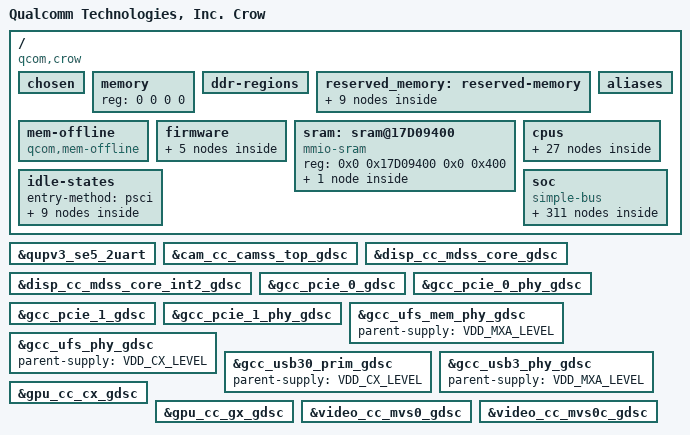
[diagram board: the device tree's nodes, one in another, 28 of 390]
#include <dt-bindings/clock/qcom,rpmh.h>
#include <dt-bindings/clock/qcom,camcc-crow.h>
#include <dt-bindings/clock/qcom,dispcc-crow.h>
#include <dt-bindings/clock/qcom,gcc-crow.h>
#include <dt-bindings/clock/qcom,gpucc-crow.h>
#include <dt-bindings/clock/qcom,tcsrcc-kalama.h>
#include <dt-bindings/clock/qcom,videocc-crow.h>
#include <dt-bindings/interconnect/qcom,icc.h>
#include <dt-bindings/interconnect/qcom,crow.h>
#include <dt-bindings/interrupt-controller/arm-gic.h>
#include <dt-bindings/soc/qcom,ipcc.h>
#include <dt-bindings/soc/qcom,rpmh-rsc.h>
#include <dt-bindings/regulator/qcom,rpmh-regulator-levels.h>
#include <dt-bindings/gpio/gpio.h>
#include <dt-bindings/spmi/spmi.h>
#include <dt-bindings/power/qcom-aoss-qmp.h>
#include <dt-bindings/clock/qcom,aop-qmp.h>

/ {
	model = "Qualcomm Technologies, Inc. Crow";
	compatible = "qcom,crow";
	qcom,msm-id = <608 0x10000>, <644 0x10000>;
	interrupt-parent = <&intc>;

	#address-cells = <2>;
	#size-cells = <2>;

	chosen: chosen {
		bootargs = "console=ttyMSM0,115200n8 loglevel=6 kpti=0 loop.max_part=7 allow_mismatched_32bit_el0 log_buf_len=256K kernel.panic_on_rcu_stall=1 service_locator.enable=1 msm_rtb.filter=0x237 rcupdate.rcu_expedited=1 rcu_nocbs=0-7 ftrace_dump_on_oops printk.console_no_auto_verbose=1 kasan=off can.stats_timer=0 pcie_ports=compat cpufreq.default_governor=performance cgroup.memory=nokmem,nosocket swiotlb=noforce disable_dma32=on page_poison=on";
		stdout-path = "/soc/qcom,qupv3_0_geni_se@8c0000/qcom,qup_uart@894000";
	};

	memory { device_type = "memory"; reg = <0 0 0 0>; };

	ddr-regions { };

	reserved_memory: reserved-memory { };

	mem-offline {
		compatible = "qcom,mem-offline";
		offline-sizes = <0x1 0x40000000 0x0 0x40000000>,
				<0x1 0xc0000000 0x0 0x80000000>,
				<0x2 0xc0000000 0x1 0x00000000>;
		granule = <512>;
		mboxes = <&qmp_aop 0>;
	};

	firmware: firmware {};

	aliases: aliases {
		serial0 = &qupv3_se5_2uart;
		ufshc1 = &ufshc_mem; /* Embedded UFS Slot */
		mmc1 = &sdhc_2; /* SDC2 SD card slot */
		hsuart0 = &qupv3_se10_4uart;
	};

	sram: sram@17D09400 {
		#address-cells = <2>;
		#size-cells = <2>;
		compatible = "mmio-sram";
		reg = <0x0 0x17D09400 0x0 0x400>;
		ranges = <0x0 0x0 0x0 0x17D09400 0x0 0x400>;

		cpu_scp_lpri: scmi-shmem@0 {
			compatible = "arm,scmi-shmem";
			reg = <0x0 0x0 0x0 0x400>;
		};
	};

	cpus {
		#address-cells = <2>;
		#size-cells = <0>;

		CPU0: cpu@0 {
			device_type = "cpu";
			compatible = "qcom,kryo";
			reg = <0x0 0x0>;
			enable-method = "psci";
			cpu-idle-states = <&SILVER_OFF &SILVER_RAIL_OFF>;
			power-domains = <&CPU_PD0>;
			power-domain-names = "psci";
			qcom,freq-domain = <&cpufreq_hw 0>;
			next-level-cache = <&L2_0>;
			capacity-dmips-mhz = <1024>;
			dynamic-power-coefficient = <100>;
			#cooling-cells = <2>;
			L2_0: l2-cache {
				compatible = "arm,arch-cache";
				cache-level = <2>;
				next-level-cache = <&L3_0>;
				L3_0: l3-cache {
					compatible = "arm,arch-cache";
					cache-level = <3>;
				};
			};
		};

		CPU1: cpu@100 {
			device_type = "cpu";
			compatible = "qcom,kryo";
			reg = <0x0 0x100>;
			enable-method = "psci";
			cpu-idle-states = <&SILVER_OFF &SILVER_RAIL_OFF>;
			power-domains = <&CPU_PD1>;
			power-domain-names = "psci";
			qcom,freq-domain = <&cpufreq_hw 0>;
			next-level-cache = <&L2_0>;
			capacity-dmips-mhz = <1024>;
			dynamic-power-coefficient = <100>;
			#cooling-cells = <2>;
		};

		CPU2: cpu@200 {
			device_type = "cpu";
			compatible = "qcom,kryo";
			reg = <0x0 0x200>;
			enable-method = "psci";
			cpu-idle-states = <&SILVER_OFF &SILVER_RAIL_OFF>;
			power-domains = <&CPU_PD2>;
			power-domain-names = "psci";
			qcom,freq-domain = <&cpufreq_hw 0>;
			next-level-cache = <&L2_2>;
			capacity-dmips-mhz = <1024>;
			dynamic-power-coefficient = <100>;
			#cooling-cells = <2>;
			L2_2: l2-cache {
				compatible = "arm,arch-cache";
				cache-level = <2>;
				next-level-cache = <&L3_0>;
			};
		};

		CPU3: cpu@300 {
			device_type = "cpu";
			compatible = "qcom,kryo";
			reg = <0x0 0x300>;
			enable-method = "psci";
			cpu-idle-states = <&SILVER_OFF &SILVER_RAIL_OFF>;
			power-domains = <&CPU_PD3>;
			power-domain-names = "psci";
			qcom,freq-domain = <&cpufreq_hw 0>;
			next-level-cache = <&L2_2>;
			capacity-dmips-mhz = <1024>;
			dynamic-power-coefficient = <100>;
			#cooling-cells = <2>;
		};

		CPU4: cpu@400 {
			device_type = "cpu";
			compatible = "qcom,kryo";
			reg = <0x0 0x400>;
			enable-method = "psci";
			cpu-idle-states = <&GOLD_OFF &GOLD_RAIL_OFF>;
			power-domains = <&CPU_PD4>;
			power-domain-names = "psci";
			qcom,freq-domain = <&cpufreq_hw 1>;
			next-level-cache = <&L2_4>;
			capacity-dmips-mhz = <1843>;
			dynamic-power-coefficient = <226>;
			#cooling-cells = <2>;
			L2_4: l2-cache {
				compatible = "arm,arch-cache";
				cache-level = <2>;
				next-level-cache = <&L3_0>;
			};
		};

		CPU5: cpu@500 {
			device_type = "cpu";
			compatible = "qcom,kryo";
			reg = <0x0 0x500>;
			enable-method = "psci";
			cpu-idle-states = <&GOLD_OFF &GOLD_RAIL_OFF>;
			power-domains = <&CPU_PD5>;
			power-domain-names = "psci";
			qcom,freq-domain = <&cpufreq_hw 1>;
			next-level-cache = <&L2_5>;
			capacity-dmips-mhz = <1843>;
			dynamic-power-coefficient = <226>;
			#cooling-cells = <2>;
			L2_5: l2-cache {
				compatible = "arm,arch-cache";
				cache-level = <2>;
				next-level-cache = <&L3_0>;
			};
		};

		CPU6: cpu@600 {
			device_type = "cpu";
			compatible = "qcom,kryo";
			reg = <0x0 0x600>;
			enable-method = "psci";
			cpu-idle-states = <&GOLD_OFF &GOLD_RAIL_OFF>;
			power-domains = <&CPU_PD6>;
			power-domain-names = "psci";
			qcom,freq-domain = <&cpufreq_hw 1>;
			next-level-cache = <&L2_6>;
			capacity-dmips-mhz = <1843>;
			dynamic-power-coefficient = <226>;
			#cooling-cells = <2>;
			L2_6: l2-cache {
				compatible = "arm,arch-cache";
				cache-level = <2>;
				next-level-cache = <&L3_0>;
				};
		};

		CPU7: cpu@700 {
			device_type = "cpu";
			compatible = "qcom,kryo";
			reg = <0x0 0x700>;
			enable-method = "psci";
			cpu-idle-states = <&GOLD_PLUS_OFF &GOLD_PLUS_RAIL_OFF>;
			power-domains = <&CPU_PD7>;
			power-domain-names = "psci";
			qcom,freq-domain = <&cpufreq_hw 2>;
			next-level-cache = <&L2_7>;
			capacity-dmips-mhz = <1853>;
			dynamic-power-coefficient = <245>;
			#cooling-cells = <2>;
			L2_7: l2-cache {
				compatible = "arm,arch-cache";
				cache-level = <2>;
				next-level-cache = <&L3_0>;
			};
		};

		cpu-map {
			cluster0 {
				core0 {
					cpu = <&CPU0>;
				};

				core1 {
					cpu = <&CPU1>;
				};

				core2 {
					cpu = <&CPU2>;
				};

				core3 {
					cpu = <&CPU3>;
				};
			};

			cluster1 {
				core0 {
					cpu = <&CPU4>;
				};

				core1 {
					cpu = <&CPU5>;
				};

				core2 {
					cpu = <&CPU6>;
				};
			};

			cluster2 {
				core0 {
					cpu = <&CPU7>;
				};
			};
		};
	};

	idle-states {
		entry-method = "psci";

		SILVER_OFF: silver-c3 {  /* C3 */
			compatible = "arm,idle-state";
			idle-state-name = "pc";
			entry-latency-us = <250>;
			exit-latency-us = <900>;
			min-residency-us = <3200>;
			arm,psci-suspend-param = <0x40000003>;
			local-timer-stop;
		};

		SILVER_RAIL_OFF: silver-c4 {  /* C4 */
			compatible = "arm,idle-state";
			idle-state-name = "rail-pc";
			entry-latency-us = <550>;
			exit-latency-us = <750>;
			min-residency-us = <6700>;
			arm,psci-suspend-param = <0x40000004>;
			local-timer-stop;
		};

		GOLD_OFF: gold-c3 {  /* C3 */
			compatible = "arm,idle-state";
			idle-state-name = "pc";
			entry-latency-us = <400>;
			exit-latency-us = <1100>;
			min-residency-us = <4011>;
			arm,psci-suspend-param = <0x40000003>;
			local-timer-stop;
		};

		GOLD_RAIL_OFF: gold-c4 {  /* C4 */
			compatible = "arm,idle-state";
			idle-state-name = "rail-pc";
			entry-latency-us = <600>;
			exit-latency-us = <1300>;
			min-residency-us = <8136>;
			arm,psci-suspend-param = <0x40000004>;
			local-timer-stop;
		};

		GOLD_PLUS_OFF: gold-plus-c3 {  /* C3 */
			compatible = "arm,idle-state";
			idle-state-name = "pc";
			entry-latency-us = <450>;
			exit-latency-us = <1200>;
			min-residency-us = <6230>;
			arm,psci-suspend-param = <0x40000003>;
			local-timer-stop;
		};

		GOLD_PLUS_RAIL_OFF: gold-plus-c4 {  /* C4 */
			compatible = "arm,idle-state";
			idle-state-name = "rail-pc";
			entry-latency-us = <500>;
			exit-latency-us = <1350>;
			min-residency-us = <7480>;
			arm,psci-suspend-param = <0x40000004>;
			local-timer-stop;
		};

		CLUSTER_PWR_DN: cluster-d4 { /* D4 */
			compatible = "domain-idle-state";
			idle-state-name = "l3-off";
			entry-latency-us = <750>;
			exit-latency-us = <2350>;
			min-residency-us = <9144>;
			arm,psci-suspend-param = <0x41000044>;
		};

		CX_RET: cx-ret { /* Cx Ret */
			compatible = "domain-idle-state";
			idle-state-name = "cx-ret";
			entry-latency-us = <1561>;
			exit-latency-us = <2801>;
			min-residency-us = <8550>;
			arm,psci-suspend-param = <0x41001344>;
		};

		APSS_OFF: cluster-e3 { /* E3 */
			compatible = "domain-idle-state";
			idle-state-name = "llcc-off";
			entry-latency-us = <2800>;
			exit-latency-us = <4400>;
			min-residency-us = <10150>;
			arm,psci-suspend-param = <0x4100b344>;
		};
	};

	soc: soc { };
};

#include "crow-reserved-memory.dtsi"
#include "crow-dma-heaps.dtsi"
#include "msm-arm-smmu-crow.dtsi"
#include "crow-coresight.dtsi"
#include "crow-debug.dtsi"

&reserved_memory {
	#address-cells = <2>;
	#size-cells = <2>;
	ranges;

	/* global autoconfigured region for contiguous allocations */
	system_cma: linux,cma {
		compatible = "shared-dma-pool";
		alloc-ranges = <0x0 0x00000000 0x0 0xffffffff>;
		reusable;
		alignment = <0x0 0x400000>;
		size = <0x0 0x2000000>;
		linux,cma-default;
	};

	ramoops_mem: ramoops_region {
		compatible = "ramoops";
		alloc-ranges = <0x0 0x00000000 0xffffffff 0xffffffff>;
		size = <0x0 0x200000>;
		pmsg-size = <0x200000>;
		mem-type = <2>;
	};

	kinfo_mem: debug_kinfo_region {
		alloc-ranges = <0x0 0x00000000 0xffffffff 0xffffffff>;
		size = <0x0 0x1000>;
		no-map;
	};

	qseecom_mem: qseecom_region {
		compatible = "shared-dma-pool";
		alloc-ranges = <0x0 0x00000000 0x0 0xffffffff>;
		reusable;
		alignment = <0x0 0x400000>;
		size = <0x0 0xC00000>;
	};

	qseecom_ta_mem: qseecom_ta_region {
		compatible = "shared-dma-pool";
		alloc-ranges = <0x0 0x00000000 0x0 0xffffffff>;
		reusable;
		alignment = <0x0 0x400000>;
		size = <0x0 0xC00000>;
	};

	adsp_mem_heap: adsp_heap_region {
		compatible = "shared-dma-pool";
		alloc-ranges = <0x0 0x00000000 0x0 0xffffffff>;
		reusable;
		alignment = <0x0 0x400000>;
		size = <0x0 0xC00000>;
	};

	cdsp_secure_heap: secure_cdsp_region { /* Secure DSP */
		compatible = "shared-dma-pool";
		alloc-ranges = <0x0 0x00000000 0x0 0xffffffff>;
		reusable;
		alignment = <0x0 0x400000>;
		size = <0x0 0x2800000>;
	};

	va_md_mem: va_md_mem_region {
		compatible = "shared-dma-pool";
		alloc-ranges = <0x0 0x00000000 0x0 0xffffffff>;
		reusable;
		size = <0 0x1000000>;
	};

	non_secure_display_memory: non_secure_display_region {
		compatible = "shared-dma-pool";
		reusable;
		alloc-ranges = <0x0 0x00000000 0x0 0xffffffff>;
		size = <0x0 0xa400000>;
		alignment = <0x0 0x400000>;
	};
};

&soc {
	#address-cells = <1>;
	#size-cells = <1>;
	ranges = <0 0 0 0xffffffff>;
	compatible = "simple-bus";

	intc: interrupt-controller@17100000 {
		compatible = "arm,gic-v3";
		#interrupt-cells = <3>;
		interrupt-controller;
		#redistributor-regions = <1>;
		redistributor-stride = <0x0 0x40000>;
		reg = <0x17100000 0x10000>,/* GICD */
			<0x17180000 0x200000>;/* GICR * 8 */
		interrupts = <GIC_PPI 9 IRQ_TYPE_LEVEL_LOW>;
	};

	apps_rsc: rsc@17a00000 {
		label = "apps_rsc";
		compatible = "qcom,rpmh-rsc";
		reg = <0x17a00000 0x10000>,
		      <0x17a10000 0x10000>,
		      <0x17a20000 0x10000>;
		reg-names = "drv-0", "drv-1", "drv-2";
		qcom,drv-count = <3>;
		interrupts = <GIC_SPI 3 IRQ_TYPE_LEVEL_HIGH>,
			     <GIC_SPI 4 IRQ_TYPE_LEVEL_HIGH>,
			     <GIC_SPI 5 IRQ_TYPE_LEVEL_HIGH>;
		power-domains = <&CLUSTER_PD>;

		apps_rsc_drv2: drv@2 {
			qcom,drv-id = <2>;
			qcom,tcs-offset = <0xd00>;
			channel@0 {
				qcom,tcs-config = <ACTIVE_TCS    3>,
						  <SLEEP_TCS     2>,
						  <WAKE_TCS      2>,
						  <CONTROL_TCS   0>,
						  <FAST_PATH_TCS 1>;
			};

			apps_bcm_voter: bcm_voter {
				compatible = "qcom,bcm-voter";
			};

			rpmhcc: clock-controller {
				compatible = "qcom,crow-rpmh-clk";
				#clock-cells = <1>;
			};

		dcvs_fp: qcom,dcvs-fp {
				compatible = "qcom,dcvs-fp";
				qcom,ddr-bcm-name = "MC4";
				qcom,llcc-bcm-name = "SH5";
			};
		};
	};

	cluster-device {
		compatible = "qcom,lpm-cluster-dev";
		power-domains = <&CLUSTER_PD>;
	};

	soc-sleep-stats@c3f0000 {
		compatible = "qcom,rpmh-sleep-stats";
		reg = <0xc3f0000 0x400>;
		qcom,drv-max = <0x14>;
		ss-name = "modem", "adsp", "adsp_island",
			  "cdsp", "apss", "wpss";
		mboxes = <&qmp_aop 0>;
		mbox-names = "aop";
		ddr-freq-update;
	};

	subsystem-sleep-stats@c3f0000 {
		compatible = "qcom,subsystem-sleep-stats";
		reg = <0xc3f0000 0x400>;
		ddr-freq-update;
	};

	cpuss-sleep-stats@17800054 {
		compatible = "qcom,cpuss-sleep-stats";
		reg = <0x17800054 0x4>, <0x17810054 0x4>, <0x17820054 0x4>,
		      <0x17830054 0x4>, <0x17840054 0x4>, <0x17850054 0x4>,
		      <0x17860054 0x4>, <0x17870054 0x4>, <0x178a0098 0x4>,
		      <0x178c0000 0x10000>;
		reg-names = "seq_lpm_cntr_cfg_cpu0", "seq_lpm_cntr_cfg_cpu1",
			    "seq_lpm_cntr_cfg_cpu2", "seq_lpm_cntr_cfg_cpu3",
			    "seq_lpm_cntr_cfg_cpu4", "seq_lpm_cntr_cfg_cpu5",
			    "seq_lpm_cntr_cfg_cpu6", "seq_lpm_cntr_cfg_cpu7",
			    "l3_seq_lpm_cntr_cfg", "apss_seq_mem_base";
		num-cpus = <8>;
	};

	disp_rsc: rsc@af20000 {
		label = "disp_rsc";
		compatible = "qcom,rpmh-rsc";
		reg = <0xaf20000 0x10000>;
		reg-names = "drv-0";
		qcom,drv-count = <1>;
		interrupts = <GIC_SPI 129 IRQ_TYPE_LEVEL_HIGH>;
		clocks = <&dispcc DISP_CC_MDSS_RSCC_AHB_CLK>;

		disp_rsc_drv0: drv@0 {
			qcom,drv-id = <0>;
			qcom,tcs-offset = <0x1c00>;
			channel@0 {
				qcom,tcs-config = <ACTIVE_TCS    0>,
						  <SLEEP_TCS     1>,
						  <WAKE_TCS      1>,
						  <CONTROL_TCS   0>,
						  <FAST_PATH_TCS 0>;
			};

			disp_bcm_voter: bcm_voter {
				compatible = "qcom,bcm-voter";
				qcom,tcs-wait = <QCOM_ICC_TAG_AMC>;
			};
		};
	};

	pdc: interrupt-controller@b220000 {
		compatible = "qcom,crow-pdc", "qcom,pdc";
		reg = <0xb220000 0x30000>, <0x174000f0 0x64>;
		qcom,pdc-ranges = <0 480 94>, <94 609 31>, <125 63 1>,
				  <126 716 12>, <138 470 5>;
		#interrupt-cells = <2>;
		interrupt-parent = <&intc>;
		interrupt-controller;
	};

	arch_timer: timer {
		compatible = "arm,armv8-timer";
		interrupts = <GIC_PPI 13 (GIC_CPU_MASK_SIMPLE(8) | IRQ_TYPE_LEVEL_LOW)>,
			     <GIC_PPI 14 (GIC_CPU_MASK_SIMPLE(8) | IRQ_TYPE_LEVEL_LOW)>,
			     <GIC_PPI 11 (GIC_CPU_MASK_SIMPLE(8) | IRQ_TYPE_LEVEL_LOW)>,
			     <GIC_PPI 12 (GIC_CPU_MASK_SIMPLE(8) | IRQ_TYPE_LEVEL_LOW)>;
		clock-frequency = <19200000>;
	};

	memtimer: timer@17420000 {
		#address-cells = <1>;
		#size-cells = <1>;
		ranges;
		compatible = "arm,armv7-timer-mem";
		reg = <0x17420000 0x1000>;
		clock-frequency = <19200000>;

		frame@17421000 {
			frame-number = <0>;
			interrupts = <GIC_SPI 8 IRQ_TYPE_LEVEL_HIGH>,
				     <GIC_SPI 6 IRQ_TYPE_LEVEL_HIGH>;
			reg = <0x17421000 0x1000>,
				<0x17422000 0x1000>;
		};

		frame@17423000 {
			frame-number = <1>;
			interrupts = <GIC_SPI 9 IRQ_TYPE_LEVEL_HIGH>;
			reg = <0x17423000 0x1000>;
			status = "disabled";
		};

		frame@17425000 {
			frame-number = <2>;
			interrupts = <GIC_SPI 10 IRQ_TYPE_LEVEL_HIGH>;
			reg = <0x17425000 0x1000>;
			status = "disabled";
		};

		frame@17427000 {
			frame-number = <3>;
			interrupts = <GIC_SPI 11 IRQ_TYPE_LEVEL_HIGH>;
			reg = <0x17427000 0x1000>;
			status = "disabled";
		};

		frame@17429000 {
			frame-number = <4>;
			interrupts = <GIC_SPI 12 IRQ_TYPE_LEVEL_HIGH>;
			reg = <0x17429000 0x1000>;
			status = "disabled";
		};

		frame@1742b000 {
			frame-number = <5>;
			interrupts = <GIC_SPI 13 IRQ_TYPE_LEVEL_HIGH>;
			reg = <0x1742b000 0x1000>;
			status = "disabled";
		};

		frame@1742d000 {
			frame-number = <6>;
			interrupts = <GIC_SPI 14 IRQ_TYPE_LEVEL_HIGH>;
			reg = <0x1742d000 0x1000>;
			status = "disabled";
		};
	};

	rimps: qcom,rimps@17400000 {
		#address-cells = <2>;
		#size-cells = <2>;
		compatible = "qcom,rimps";
		reg =   <0x17400000 0x10>,
			<0x17d90000 0x2000>;
		#mbox-cells = <1>;
		interrupts = <GIC_SPI 62 IRQ_TYPE_LEVEL_HIGH>;
	};

	scmi: qcom,scmi {
		#address-cells = <1>;
		#size-cells = <0>;
		compatible = "arm,scmi";
		mboxes = <&rimps 0>;
		mbox-names = "tx";
		shmem = <&cpu_scp_lpri>;

		scmi_memlat: protocol@80 {
			reg = <0x80>;
			#clock-cells = <1>;
		};

		scmi_plh: protocol@81 {
			reg = <0x81>;
			#clock-cells = <1>;
		};

		scmi_cpufreqstat: protocol@84 {
			reg = <0x84>;
			#clock-cells = <1>;
		};

		scmi_c1dcvs: protocol@87 {
			reg = <0x87>;
			#clock-cells = <1>;
		};

	};

	rimps_log: qcom,rimps_log@d8140000 {
		compatible = "qcom,rimps-log";
		reg = <0xd8140000 0x10000>, <0xd8150000 0x10000>;
		mboxes = <&rimps 1>;
	};

	ipcc_mproc: qcom,ipcc@408000 {
		compatible = "qcom,ipcc";
		reg = <0x408000 0x1000>;
		interrupts = <GIC_SPI 229 IRQ_TYPE_LEVEL_HIGH>;
		interrupt-controller;
		#interrupt-cells = <3>;
		#mbox-cells = <2>;
	};

	qcom,msm-cdsp-loader {
		compatible = "qcom,cdsp-loader";
		qcom,proc-img-to-load = "cdsp";
		qcom,rproc-handle = <&cdsp_pas>;
	};

	qcom,msm-adsprpc-mem {
		compatible = "qcom,msm-adsprpc-mem-region";
		memory-region = <&adsp_mem_heap>;
		restrict-access;
	};

	msm_fastrpc: qcom,msm_fastrpc {
		compatible = "qcom,msm-fastrpc-compute";
		qcom,adsp-remoteheap-vmid = <22 37>;
		qcom,fastrpc-adsp-audio-pdr;
		qcom,fastrpc-adsp-sensors-pdr;
		qcom,rpc-latency-us = <235>;
		qcom,fastrpc-gids = <2908>;
		qcom,qos-cores = <0 1 2 3>;

		qcom,msm_fastrpc_compute_cb1 {
			compatible = "qcom,msm-fastrpc-compute-cb";
			label = "cdsprpc-smd";
			iommus = <&apps_smmu 0x0C01 0x0000>;
			qcom,iommu-dma-addr-pool = <0x60000000 0x98000000>;
			qcom,iommu-faults = "stall-disable", "HUPCF";
			dma-coherent;
		};

		qcom,msm_fastrpc_compute_cb2 {
			compatible = "qcom,msm-fastrpc-compute-cb";
			label = "cdsprpc-smd";
			iommus = <&apps_smmu 0x0C02 0x0000>;
			qcom,iommu-dma-addr-pool = <0x60000000 0x98000000>;
			qcom,iommu-faults = "stall-disable", "HUPCF";
			dma-coherent;
		};

		qcom,msm_fastrpc_compute_cb3 {
			compatible = "qcom,msm-fastrpc-compute-cb";
			label = "cdsprpc-smd";
			iommus = <&apps_smmu 0x0C03 0x0000>;
			qcom,iommu-dma-addr-pool = <0x60000000 0x98000000>;
			qcom,iommu-faults = "stall-disable", "HUPCF";
			dma-coherent;
		};

		qcom,msm_fastrpc_compute_cb4 {
			compatible = "qcom,msm-fastrpc-compute-cb";
			label = "cdsprpc-smd";
			iommus = <&apps_smmu 0x0C04 0x0000>;
			qcom,iommu-dma-addr-pool = <0x60000000 0x98000000>;
			qcom,iommu-faults = "stall-disable", "HUPCF";
			dma-coherent;
		};

		qcom,msm_fastrpc_compute_cb5 {
			compatible = "qcom,msm-fastrpc-compute-cb";
			label = "cdsprpc-smd";
			iommus = <&apps_smmu 0x0C05 0x0000>;
			qcom,iommu-dma-addr-pool = <0x60000000 0x98000000>;
			qcom,iommu-faults = "stall-disable", "HUPCF";
			dma-coherent;
		};

		qcom,msm_fastrpc_compute_cb6 {
			compatible = "qcom,msm-fastrpc-compute-cb";
			label = "cdsprpc-smd";
			iommus = <&apps_smmu 0x0C06 0x0000>;
			qcom,iommu-dma-addr-pool = <0x60000000 0x98000000>;
			qcom,iommu-faults = "stall-disable", "HUPCF";
			dma-coherent;
		};

		qcom,msm_fastrpc_compute_cb7 {
			compatible = "qcom,msm-fastrpc-compute-cb";
			label = "cdsprpc-smd";
			iommus = <&apps_smmu 0x0C07 0x0000>;
			qcom,iommu-dma-addr-pool = <0x60000000 0x98000000>;
			qcom,iommu-faults = "stall-disable", "HUPCF";
			dma-coherent;
		};

		qcom,msm_fastrpc_compute_cb8 {
			compatible = "qcom,msm-fastrpc-compute-cb";
			label = "cdsprpc-smd";
			iommus = <&apps_smmu 0x0C08 0x0000>;
			qcom,iommu-dma-addr-pool = <0x60000000 0x98000000>;
			qcom,iommu-faults = "stall-disable", "HUPCF";
			dma-coherent;
		};

		qcom,msm_fastrpc_compute_cb9 {
			compatible = "qcom,msm-fastrpc-compute-cb";
			label = "cdsprpc-smd";
			qcom,secure-context-bank;
			iommus = <&apps_smmu 0x0C09 0x0000>;
			qcom,iommu-dma-addr-pool = <0x40000000 0x98000000>;
			qcom,iommu-faults = "stall-disable", "HUPCF";
			qcom,iommu-vmid = <0xA>;	/* VMID_CP_PIXEL */
			dma-coherent;
		};

		qcom,msm_fastrpc_compute_cb10 {
			compatible = "qcom,msm-fastrpc-compute-cb";
			label = "adsprpc-smd";
			iommus = <&apps_smmu 0x1003 0x0000>,
				 <&apps_smmu 0x1063 0x0000>;
			qcom,iommu-dma-addr-pool = <0x60000000 0x98000000>;
			qcom,iommu-faults = "stall-disable", "HUPCF";
			dma-coherent;
		};

		qcom,msm_fastrpc_compute_cb11 {
			compatible = "qcom,msm-fastrpc-compute-cb";
			label = "adsprpc-smd";
			iommus = <&apps_smmu 0x1004 0x0000>,
				 <&apps_smmu 0x1064 0x0000>;
			qcom,iommu-dma-addr-pool = <0x60000000 0x98000000>;
			qcom,iommu-faults = "stall-disable", "HUPCF";
			dma-coherent;
		};

		qcom,msm_fastrpc_compute_cb12 {
			compatible = "qcom,msm-fastrpc-compute-cb";
			label = "adsprpc-smd";
			iommus = <&apps_smmu 0x1005 0x0000>,
				 <&apps_smmu 0x1065 0x0000>;
			qcom,iommu-dma-addr-pool = <0x60000000 0x98000000>;
			qcom,iommu-faults = "stall-disable", "HUPCF";
			shared-cb = <5>;
			dma-coherent;
		};

		qcom,msm_fastrpc_compute_cb13 {
			compatible = "qcom,msm-fastrpc-compute-cb";
			label = "adsprpc-smd";
			iommus = <&apps_smmu 0x1006 0x0000>,
				 <&apps_smmu 0x1066 0x0000>;
			qcom,iommu-dma-addr-pool = <0x60000000 0x98000000>;
			qcom,iommu-faults = "stall-disable", "HUPCF";
			dma-coherent;
		};

		qcom,msm_fastrpc_compute_cb14 {
			compatible = "qcom,msm-fastrpc-compute-cb";
			label = "cdsprpc-smd";
			iommus = <&apps_smmu 0x0C0C 0x0000>;
			qcom,iommu-dma-addr-pool = <0x60000000 0x98000000>;
			qcom,iommu-faults = "stall-disable", "HUPCF";
			dma-coherent;
		};

		qcom,msm_fastrpc_compute_cb15 {
			compatible = "qcom,msm-fastrpc-compute-cb";
			label = "cdsprpc-smd";
			iommus = <&apps_smmu 0x0C0D 0x0000>;
			qcom,iommu-dma-addr-pool = <0x60000000 0x98000000>;
			qcom,iommu-faults = "stall-disable", "HUPCF";
			dma-coherent;
		};

		qcom,msm_fastrpc_compute_cb16 {
			compatible = "qcom,msm-fastrpc-compute-cb";
			label = "cdsprpc-smd";
			iommus = <&apps_smmu 0x0C0E 0x0000>;
			qcom,iommu-dma-addr-pool = <0x60000000 0x98000000>;
			qcom,iommu-faults = "stall-disable", "HUPCF";
			dma-coherent;
		};

		qcom,msm_fastrpc_compute_cb17 {
			compatible = "qcom,msm-fastrpc-compute-cb";
			label = "cdsprpc-smd";
			iommus = <&apps_smmu 0x0C0F 0x0000>;
			qcom,iommu-dma-addr-pool = <0x60000000 0x98000000>;
			qcom,iommu-faults = "stall-disable", "HUPCF";
			dma-coherent;
		};
	};

	aoss_qmp: power-controller@c300000 {
		compatible = "qcom,kalama-aoss-qmp";
		reg = <0xc300000 0x400>;
		interrupt-parent = <&ipcc_mproc>;
		interrupts = <IPCC_CLIENT_AOP
			      IPCC_MPROC_SIGNAL_GLINK_QMP
			      IRQ_TYPE_EDGE_RISING>;
		mboxes = <&ipcc_mproc IPCC_CLIENT_AOP
			  IPCC_MPROC_SIGNAL_GLINK_QMP>;

		#power-domain-cells = <1>;
		#clock-cells = <0>;
	};

	qmp_aop: qcom,qmp-aop {
		compatible = "qcom,qmp-mbox";
		qcom,qmp = <&aoss_qmp>;
		label = "aop";
		#mbox-cells = <1>;
	};

	qmp_tme: qcom,qmp-tme {
		compatible = "qcom,qmp-mbox";
		qcom,remote-pid = <14>;
		mboxes = <&ipcc_mproc IPCC_CLIENT_TME
			  IPCC_MPROC_SIGNAL_GLINK_QMP>;
		mbox-names = "tme_qmp";
		interrupt-parent = <&ipcc_mproc>;
		interrupts = <IPCC_CLIENT_TME
			      IPCC_MPROC_SIGNAL_GLINK_QMP
			      IRQ_TYPE_EDGE_RISING>;

		label = "tme";
		qcom,early-boot;
		priority = <0>;
		mbox-desc-offset = <0x0>;
		#mbox-cells = <1>;
	};
	com,tmecom-qmp-client {
		compatible = "qcom,tmecom-qmp-client";
		mboxes = <&qmp_tme 0>;
		mbox-names = "tmecom";
		label = "tmecom";
		depends-on-supply = <&qmp_tme>;
	};

	tcsr: syscon@1fc0000 {
		compatible = "syscon";
		reg = <0x1fc0000 0x30000>;
	};

	tcsr_mutex_block: syscon@1f40000 {
		compatible = "syscon";
		reg = <0x1f40000 0x20000>;
	};

	tcsr_mutex: hwlock {
		compatible = "qcom,tcsr-mutex";
		syscon = <&tcsr_mutex_block 0 0x1000>;
		#hwlock-cells = <1>;
	};

	smem: qcom,smem {
		compatible = "qcom,smem";
		memory-region = <&smem_mem>;
		depends-on-supply = <&tcsr_mutex>;
		hwlocks = <&tcsr_mutex 3>;
	};

	qcom,smp2p-adsp {
		compatible = "qcom,smp2p";
		qcom,smem = <443>, <429>;
		interrupt-parent = <&ipcc_mproc>;
		interrupts = <IPCC_CLIENT_LPASS IPCC_MPROC_SIGNAL_SMP2P
			      IRQ_TYPE_EDGE_RISING>;
		mboxes = <&ipcc_mproc IPCC_CLIENT_LPASS
			  IPCC_MPROC_SIGNAL_SMP2P>;
		qcom,local-pid = <0>;
		qcom,remote-pid = <2>;

		adsp_smp2p_out: master-kernel {
			qcom,entry-name = "master-kernel";
			#qcom,smem-state-cells = <1>;
		};

		adsp_smp2p_in: slave-kernel {
			qcom,entry-name = "slave-kernel";
			interrupt-controller;
			#interrupt-cells = <2>;
		};

		sleepstate_smp2p_out: sleepstate-out {
			qcom,entry-name = "sleepstate";
			#qcom,smem-state-cells = <1>;
		};

		sleepstate_smp2p_in: qcom,sleepstate-in {
			qcom,entry-name = "sleepstate_see";
			interrupt-controller;
			#interrupt-cells = <2>;
		};

		smp2p_rdbg2_out: qcom,smp2p-rdbg2-out {
			qcom,entry-name = "rdbg";
			#qcom,smem-state-cells = <1>;
		};

		smp2p_rdbg2_in: qcom,smp2p-rdbg2-in {
			qcom,entry-name = "rdbg";
			interrupt-controller;
			#interrupt-cells = <2>;
		};
	};

	qcom,smp2p-cdsp {
		compatible = "qcom,smp2p";
		qcom,smem = <94>, <432>;
		interrupt-parent = <&ipcc_mproc>;
		interrupts = <IPCC_CLIENT_CDSP IPCC_MPROC_SIGNAL_SMP2P
			      IRQ_TYPE_EDGE_RISING>;
		mboxes = <&ipcc_mproc IPCC_CLIENT_CDSP IPCC_MPROC_SIGNAL_SMP2P>;
		qcom,local-pid = <0>;
		qcom,remote-pid = <5>;

		cdsp_smp2p_out: master-kernel {
			qcom,entry-name = "master-kernel";
			#qcom,smem-state-cells = <1>;
		};

		cdsp_smp2p_in: slave-kernel {
			qcom,entry-name = "slave-kernel";
			interrupt-controller;
			#interrupt-cells = <2>;
		};

		smp2p_rdbg5_out: qcom,smp2p-rdbg5-out {
			qcom,entry-name = "rdbg";
			#qcom,smem-state-cells = <1>;
		};

		smp2p_rdbg5_in: qcom,smp2p-rdbg5-in {
			qcom,entry-name = "rdbg";
			interrupt-controller;
			#interrupt-cells = <2>;
		};
	};

	qcom,smp2p-modem {
		compatible = "qcom,smp2p";
		qcom,smem = <435>, <428>;
		interrupt-parent = <&ipcc_mproc>;
		interrupts = <IPCC_CLIENT_MPSS IPCC_MPROC_SIGNAL_SMP2P
			      IRQ_TYPE_EDGE_RISING>;
		mboxes = <&ipcc_mproc IPCC_CLIENT_MPSS IPCC_MPROC_SIGNAL_SMP2P>;
		qcom,local-pid = <0>;
		qcom,remote-pid = <1>;

		modem_smp2p_out: master-kernel {
			qcom,entry-name = "master-kernel";
			#qcom,smem-state-cells = <1>;
		};

		modem_smp2p_in: slave-kernel {
			qcom,entry-name = "slave-kernel";
			interrupt-controller;
			#interrupt-cells = <2>;
		};

		smp2p_ipa_1_out: qcom,smp2p-ipa-1-out {
			qcom,entry-name = "ipa";
			#qcom,smem-state-cells = <1>;
		};

		/* ipa - inbound entry from mss */
		smp2p_ipa_1_in: qcom,smp2p-ipa-1-in {
			qcom,entry-name = "ipa";
			interrupt-controller;
			#interrupt-cells = <2>;
		};
	};

	qcom,smp2p_sleepstate {
		compatible = "qcom,smp2p-sleepstate";
		qcom,smem-states = <&sleepstate_smp2p_out 0>;
		interrupt-parent = <&sleepstate_smp2p_in>;
		interrupts = <0 0>;
		interrupt-names = "smp2p-sleepstate-in";
	};

	qcom,smp2p-wpss {
		compatible = "qcom,smp2p";
		qcom,smem = <617>, <616>;
		interrupt-parent = <&ipcc_mproc>;
		interrupts = <IPCC_CLIENT_WPSS IPCC_MPROC_SIGNAL_SMP2P
			IRQ_TYPE_EDGE_RISING>;
		mboxes = <&ipcc_mproc IPCC_CLIENT_WPSS IPCC_MPROC_SIGNAL_SMP2P>;
		qcom,local-pid = <0>;
		qcom,remote-pid = <13>;

		wpss_smp2p_out: master-kernel {
			qcom,entry-name = "master-kernel";
			#qcom,smem-state-cells = <1>;
		};

		wpss_smp2p_in: slave-kernel {
			qcom,entry-name = "slave-kernel";
			interrupt-controller;
			#interrupt-cells = <2>;
		};
	};

	sdhc2_opp_table: sdhc2-opp-table {
		compatible = "operating-points-v2";

		opp-100000000 {
			opp-hz = /bits/ 64 <100000000>;
			opp-peak-kBps = <1600000 280000>;
			opp-avg-kBps = <50000 0>;
		};

		opp-202000000 {
			opp-hz = /bits/ 64 <202000000>;
			opp-peak-kBps = <5600000 1500000>;
			opp-avg-kBps = <104000 0>;
		};
	};

	sdhc_2: sdhci@8804000 {
		status = "disabled";

		compatible = "qcom,sdhci-msm-v5";
		reg = <0x08804000 0x1000>;
		reg-names = "hc_mem";

		interrupts = <GIC_SPI 207 IRQ_TYPE_LEVEL_HIGH>,
				<GIC_SPI 223 IRQ_TYPE_LEVEL_HIGH>;
		interrupt-names = "hc_irq", "pwr_irq";

		bus-width = <4>;
		no-sdio;
		no-mmc;
		qcom,uses_level_shifter;

		clocks = <&gcc GCC_SDCC2_AHB_CLK>,
			<&gcc GCC_SDCC2_APPS_CLK>;
		clock-names = "iface", "core";

		/*
		 * DLL HSR settings. Refer go/hsr - <Target> DLL settings.
		 * Note that the DLL_CONFIG_2 value is not passed from the
		 * device tree, but it is calculated in the driver.
		 */
		qcom,dll-hsr-list = <0x0007442C 0x0 0x10
					0x090106C0 0x80040868>;

		iommus = <&apps_smmu 0x4C0 0x0>;
		dma-coherent;
		qcom,iommu-dma = "fastmap";

		qcom,iommu-dma-addr-pool = <0x40000000 0x10000000>;
		qcom,iommu-geometry = <0x40000000 0x10000000>;

		interconnects = <&aggre2_noc MASTER_SDCC_2 &mc_virt SLAVE_EBI1>,
				<&gem_noc MASTER_APPSS_PROC &config_noc SLAVE_SDCC_2>;
		interconnect-names = "sdhc-ddr","cpu-sdhc";
		operating-points-v2 = <&sdhc2_opp_table>;

		qos0 {
			mask = <0xf0>;
			vote = <44>;
		};

		qos1 {
			mask = <0x0f>;
			vote = <44>;
		};
	};

	qcom,glinkpkt {
		compatible = "qcom,glinkpkt";

		qcom,glinkpkt-at-mdm0 {
			qcom,glinkpkt-edge = "mpss";
			qcom,glinkpkt-ch-name = "DS";
			qcom,glinkpkt-dev-name = "at_mdm0";
		};

		qcom,glinkpkt-apr-apps2 {
			qcom,glinkpkt-edge = "adsp";
			qcom,glinkpkt-ch-name = "apr_apps2";
			qcom,glinkpkt-dev-name = "apr_apps2";
		};

		qcom,glinkpkt-data40-cntl {
			qcom,glinkpkt-edge = "mpss";
			qcom,glinkpkt-ch-name = "DATA40_CNTL";
			qcom,glinkpkt-dev-name = "smdcntl8";
		};

		qcom,glinkpkt-data1 {
			qcom,glinkpkt-edge = "mpss";
			qcom,glinkpkt-ch-name = "DATA1";
			qcom,glinkpkt-dev-name = "smd7";
		};

		qcom,glinkpkt-data4 {
			qcom,glinkpkt-edge = "mpss";
			qcom,glinkpkt-ch-name = "DATA4";
			qcom,glinkpkt-dev-name = "smd8";
		};

		qcom,glinkpkt-data11 {
			qcom,glinkpkt-edge = "mpss";
			qcom,glinkpkt-ch-name = "DATA11";
			qcom,glinkpkt-dev-name = "smd11";
		};

		qcom,glinkpkt-xpan_control {
			qcom,glinkpkt-edge = "adsp";
			qcom,glinkpkt-ch-name = "bt_cp_ctrl";
			qcom,glinkpkt-dev-name = "bt_cp_ctrl";
		};
	};

	qcom,glink {
		compatible = "qcom,glink";
	};

	psci {
		compatible = "arm,psci-1.0";
		method = "smc";

		CPU_PD0: cpu-pd0 {
			#power-domain-cells = <0>;
			power-domains = <&CLUSTER_PD>;
		};

		CPU_PD1: cpu-pd1 {
			#power-domain-cells = <0>;
			power-domains = <&CLUSTER_PD>;
		};

		CPU_PD2: cpu-pd2 {
			#power-domain-cells = <0>;
			power-domains = <&CLUSTER_PD>;
		};

		CPU_PD3: cpu-pd3 {
			#power-domain-cells = <0>;
			power-domains = <&CLUSTER_PD>;
		};

		CPU_PD4: cpu-pd4 {
			#power-domain-cells = <0>;
			power-domains = <&CLUSTER_PD>;
		};

		CPU_PD5: cpu-pd5 {
			#power-domain-cells = <0>;
			power-domains = <&CLUSTER_PD>;
		};

		CPU_PD6: cpu-pd6 {
			#power-domain-cells = <0>;
			power-domains = <&CLUSTER_PD>;
		};

		CPU_PD7: cpu-pd7 {
			#power-domain-cells = <0>;
			power-domains = <&CLUSTER_PD>;
		};

		CLUSTER_PD: cluster-pd {
			#power-domain-cells = <0>;
			domain-idle-states = <&CLUSTER_PWR_DN &CX_RET &APSS_OFF>;
		};
	};

	slimbam: bamdma@3304000 {
		compatible = "qcom,bam-v1.7.0";
		qcom,controlled-remotely;
		reg = <0x3304000 0x20000>, <0x326B000 0x1000>;
		reg-names = "bam", "bam_remote_mem";
		num-channels  = <31>;
		interrupts = <0 164 IRQ_TYPE_LEVEL_HIGH>;
		#dma-cells = <1>;
		qcom,ee = <1>;
		qcom,num-ees = <2>;
	};

	slim_msm: slim@3340000 {
		compatible = "qcom,slim-ngd-v1.5.0";
		reg = <0x3340000 0x2C000>, <0x326A000 0x1000>;
		reg-names = "ctrl", "slimbus_remote_mem";
		interrupts = <0 163 IRQ_TYPE_LEVEL_HIGH>;
		qcom,apps-ch-pipes = <0x0>;
		qcom,ea-pc = <0x4D0>;
		dmas = <&slimbam 3>, <&slimbam 4>;
		dma-names = "rx", "tx";
		#address-cells = <1>;
		#size-cells = <0>;
		status = "disabled";
	};

	clk_virt: interconnect@0 {
		compatible = "qcom,crow-clk_virt";
		#interconnect-cells = <1>;
		qcom,bcm-voter-names = "hlos";
		qcom,bcm-voters = <&apps_bcm_voter>;
	};

	mc_virt: interconnect@1 {
		compatible = "qcom,crow-mc_virt";
		#interconnect-cells = <1>;
		qcom,bcm-voter-names = "hlos", "disp";
		qcom,bcm-voters = <&apps_bcm_voter>, <&disp_bcm_voter>;
	};

	config_noc: interconnect@1600000 {
		compatible = "qcom,crow-cnoc_cfg";
		reg = <0x01600000 0x9080>;
		#interconnect-cells = <1>;
		qcom,bcm-voter-names = "hlos";
		qcom,bcm-voters = <&apps_bcm_voter>;
	};

	cnoc_main: interconnect@1500000 {
		compatible = "qcom,crow-cnoc_main";
		reg = <0x1500000 0x13080>;
		#interconnect-cells = <1>;
		qcom,bcm-voter-names = "hlos";
		qcom,bcm-voters = <&apps_bcm_voter>;
	};

	system_noc: interconnect@1680000 {
		compatible = "qcom,crow-system_noc";
		reg = <0x01680000 0x1D080>;
		#interconnect-cells = <1>;
		qcom,bcm-voter-names = "hlos";
		qcom,bcm-voters = <&apps_bcm_voter>;
	};

	pcie_noc: interconnect@16c0000 {
		compatible = "qcom,crow-pcie_anoc";
		reg = <0x016C0000 0x12200>;
		#interconnect-cells = <1>;
		clocks = <&gcc GCC_AGGRE_NOC_PCIE_AXI_CLK>,
			 <&gcc GCC_CFG_NOC_PCIE_ANOC_AHB_CLK>;
		qcom,bcm-voter-names = "hlos";
		qcom,bcm-voters = <&apps_bcm_voter>;
	};

	aggre1_noc: interconnect@16e0000 {
		compatible = "qcom,crow-aggre1_noc";
		reg = <0x016E0000 0x14400>;
		#interconnect-cells = <1>;
		clocks =
			<&gcc GCC_AGGRE_UFS_PHY_AXI_CLK>,
			<&gcc GCC_AGGRE_USB3_PRIM_AXI_CLK>;
		qcom,bcm-voter-names = "hlos";
		qcom,bcm-voters = <&apps_bcm_voter>;
	};

	aggre2_noc: interconnect@1700000 {
		compatible = "qcom,crow-aggre2_noc";
		reg = <0x01700000 0x1F400>;
		#interconnect-cells = <1>;
		clocks = <&rpmhcc RPMH_IPA_CLK>;
		qcom,bcm-voter-names = "hlos";
		qcom,bcm-voters = <&apps_bcm_voter>;
	};

	mmss_noc: interconnect@1780000 {
		compatible = "qcom,crow-mmss_noc";
		reg = <0x01780000 0x5b800>;
		#interconnect-cells = <1>;
		qcom,bcm-voter-names = "hlos", "disp";
		qcom,bcm-voters = <&apps_bcm_voter>, <&disp_bcm_voter>;
	};

	gem_noc: interconnect@24100000 {
		compatible = "qcom,crow-gem_noc";
		reg = <0x24100000 0xBD080>;
		#interconnect-cells = <1>;
		qcom,bcm-voter-names = "hlos", "disp";
		qcom,bcm-voters = <&apps_bcm_voter>, <&disp_bcm_voter>;
	};

	nsp_noc: interconnect@320c0000 {
		compatible = "qcom,crow-nsp_noc";
		reg = <0x320C0000 0xE080>;
		#interconnect-cells = <1>;
		qcom,bcm-voter-names = "hlos";
		qcom,bcm-voters = <&apps_bcm_voter>;
	};

	lpass_ag_noc: interconnect@3C40000 {
		compatible = "qcom,crow-lpass_ag_noc";
		reg = <0x03C40000 0x17200>;
		#interconnect-cells = <1>;
		qcom,bcm-voter-names = "hlos";
		qcom,bcm-voters = <&apps_bcm_voter>;
	};

	clocks {
		xo_board: xo_board {
			compatible = "fixed-clock";
			clock-frequency = <76800000>;
			clock-output-names = "xo_board";
			#clock-cells = <0>;
		};

		sleep_clk: sleep_clk {
			compatible = "fixed-clock";
			clock-frequency = <32000>;
			clock-output-names = "sleep_clk";
			#clock-cells = <0>;
		};

		gcc_jdr_ctrl_pll_tcg_mux_clk_src: gcc_jdr_ctrl_pll_tcg_mux_clk_src {
			compatible = "fixed-clock";
			clock-frequency = <1000>;
			clock-output-names = "gcc_jdr_ctrl_pll_tcg_mux_clk_src";
			#clock-cells = <0>;
		};

		pcie_0_pipe_clk: pcie_0_pipe_clk {
			compatible = "fixed-clock";
			clock-frequency = <1000>;
			clock-output-names = "pcie_0_pipe_clk";
			#clock-cells = <0>;
		};

		pcie_1_phy_aux_clk: pcie_1_phy_aux_clk {
			compatible = "fixed-clock";
			clock-frequency = <1000>;
			clock-output-names = "pcie_1_phy_aux_clk";
			#clock-cells = <0>;
		};

		pcie_1_pipe_clk: pcie_1_pipe_clk {
			compatible = "fixed-clock";
			clock-frequency = <1000>;
			clock-output-names = "pcie_1_pipe_clk";
			#clock-cells = <0>;
		};

		ufs_phy_rx_symbol_0_clk: ufs_phy_rx_symbol_0_clk {
			compatible = "fixed-clock";
			clock-frequency = <1000>;
			clock-output-names = "ufs_phy_rx_symbol_0_clk";
			#clock-cells = <0>;
		};

		ufs_phy_rx_symbol_1_clk: ufs_phy_rx_symbol_1_clk {
			compatible = "fixed-clock";
			clock-frequency = <1000>;
			clock-output-names = "ufs_phy_rx_symbol_1_clk";
			#clock-cells = <0>;
		};

		ufs_phy_tx_symbol_0_clk: ufs_phy_tx_symbol_0_clk {
			compatible = "fixed-clock";
			clock-frequency = <1000>;
			clock-output-names = "ufs_phy_tx_symbol_0_clk";
			#clock-cells = <0>;
		};

		usb3_phy_wrapper_gcc_usb30_pipe_clk: usb3_phy_wrapper_gcc_usb30_pipe_clk {
			compatible = "fixed-clock";
			clock-frequency = <1000>;
			clock-output-names = "usb3_phy_wrapper_gcc_usb30_pipe_clk";
			#clock-cells = <0>;
		};
	};

	camcc: clock-controller@adb0000 {
		compatible = "qcom,crow-camcc", "syscon";
		reg = <0xadb0000 0x40000>;
		reg-name = "cc_base";
		vdd_cx-supply = <&VDD_CX_LEVEL>;
		vdd_mxa-supply = <&VDD_MXA_LEVEL>;
		vdd_mxc-supply = <&VDD_MXC_LEVEL>;
		clocks = <&rpmhcc RPMH_CXO_CLK>,
			<&rpmhcc RPMH_CXO_CLK_A>,
			 <&sleep_clk>,
			 <&gcc GCC_CAMERA_AHB_CLK>;
		clock-names = "bi_tcxo",
			      "bi_tcxo_ao",
			      "sleep_clk",
			      "iface";
		#clock-cells = <1>;
		#reset-cells = <1>;
	};

	dispcc: clock-controller@af00000 {
		compatible = "qcom,crow-dispcc", "syscon";
		reg = <0xaf00000 0x20000>;
		reg-name = "cc_base";
		vdd_cx-supply = <&VDD_CX_LEVEL>;
		vdd_mxa-supply = <&VDD_MXA_LEVEL>;
		clocks = <&rpmhcc RPMH_CXO_CLK>,
			<&rpmhcc RPMH_CXO_CLK_A>,
			<&sleep_clk>,
			<&gcc GCC_DISP_AHB_CLK>;
		clock-names = "bi_tcxo",
			      "bi_tcxo_ao",
			      "sleep_clk",
			      "iface";
		#clock-cells = <1>;
		#reset-cells = <1>;
	};

	gcc: clock-controller@100000 {
		compatible = "qcom,crow-gcc", "syscon";
		reg = <0x100000 0x1f4200>;
		reg-name = "cc_base";
		vdd_cx-supply = <&VDD_CX_LEVEL>;
		vdd_mxa-supply = <&VDD_MXA_LEVEL>;
		clocks = <&rpmhcc RPMH_CXO_CLK>,
			 <&pcie_0_pipe_clk>,
			 <&pcie_1_phy_aux_clk>,
			 <&pcie_1_pipe_clk>,
			 <&sleep_clk>,
			 <&ufs_phy_rx_symbol_0_clk>,
			 <&ufs_phy_rx_symbol_1_clk>,
			 <&ufs_phy_tx_symbol_0_clk>,
			 <&usb3_phy_wrapper_gcc_usb30_pipe_clk>;
		clock-names = "bi_tcxo",
			      "pcie_0_pipe_clk",
			      "pcie_1_phy_aux_clk",
			      "pcie_1_pipe_clk",
			      "sleep_clk",
			      "ufs_phy_rx_symbol_0_clk",
			      "ufs_phy_rx_symbol_1_clk",
			      "ufs_phy_tx_symbol_0_clk",
			      "usb3_phy_wrapper_gcc_usb30_pipe_clk";
		clock-output-names = "gcc_clocks";
		#clock-cells = <1>;
		#reset-cells = <1>;
	};

	gpucc: clock-controller@3d90000 {
		compatible = "qcom,crow-gpucc", "syscon";
		reg = <0x3d90000 0xa000>;
		reg-name = "cc_base";
		vdd_cx-supply = <&VDD_CX_LEVEL>;
		vdd_mx-supply = <&VDD_MXA_LEVEL>;
		vdd_mxc-supply = <&VDD_MXC_LEVEL>;
		clocks = <&rpmhcc RPMH_CXO_CLK>,
			<&rpmhcc RPMH_CXO_CLK_A>,
			 <&gcc GCC_GPU_GPLL0_CLK_SRC>,
			 <&gcc GCC_GPU_GPLL0_DIV_CLK_SRC>;
		clock-names = "bi_tcxo",
			      "bi_tcxo_ao",
			      "gpll0_out_main",
			      "gpll0_out_main_div";
		#clock-cells = <1>;
		#reset-cells = <1>;
	};

	tcsrcc: clock-controller@1fc0000 {
		compatible = "qcom,kalama-tcsrcc", "syscon";
		reg = <0x1fc0000 0x30000>;
		reg-name = "cc_base";
		#clock-cells = <1>;
		#reset-cells = <1>;
	};

	videocc: clock-controller@aaf0000 {
		compatible = "qcom,crow-videocc", "syscon";
		reg = <0xaaf0000 0x10000>;
		reg-name = "cc_base";
		vdd_cx-supply = <&VDD_CX_LEVEL>;
		vdd_mxc-supply = <&VDD_MXC_LEVEL>;
		clocks = <&rpmhcc RPMH_CXO_CLK>,
			 <&rpmhcc RPMH_CXO_CLK_A>,
			 <&sleep_clk>,
			 <&gcc GCC_VIDEO_AHB_CLK>;
		clock-names = "bi_tcxo",
			      "bi_tcxo_ao",
			      "sleep_clk",
			      "iface";
		#clock-cells = <1>;
		#reset-cells = <1>;
	};

	cpufreq_hw: qcom,cpufreq-hw {
		compatible = "qcom,cpufreq-epss";
		reg = <0x17D91000 0x1000>,
		      <0x17D92000 0x1000>,
		      <0x17D93000 0x1000>;
		reg-names = "freq-domain0",
			    "freq-domain1",
			    "freq-domain2";
		clocks = <&rpmhcc RPMH_CXO_CLK>, <&gcc GCC_GPLL0>;
		clock-names = "xo", "alternate";
		interrupts = <GIC_SPI 30 IRQ_TYPE_LEVEL_HIGH>,
			     <GIC_SPI 31 IRQ_TYPE_LEVEL_HIGH>,
			     <GIC_SPI 19 IRQ_TYPE_LEVEL_HIGH>;
		interrupt-names = "dcvsh0_int",
				  "dcvsh1_int",
				  "dcvsh2_int";
		#freq-domain-cells = <1>;
	};

	qcom,cpufreq-hw-debug {
		compatible = "qcom,cpufreq-hw-epss-debug";
		qcom,freq-hw-domain = <&cpufreq_hw 0>,
				      <&cpufreq_hw 1>,
				      <&cpufreq_hw 2>;
	};

	apsscc: syscon@17a80000 {
		compatible = "syscon";
		reg = <0x17a80000 0x21000>;
	};

	mccc: syscon@240ba000 {
		compatible = "syscon";
		reg = <0x240ba000 0x54>;
	};

	debugcc: clock-controller@0 {
		compatible = "qcom,crow-debugcc";
		qcom,apsscc = <&apsscc>;
		qcom,camcc = <&camcc>;
		qcom,dispcc = <&dispcc>;
		qcom,gcc = <&gcc>;
		qcom,gpucc = <&gpucc>;
		qcom,mccc = <&mccc>;
		qcom,tcsrcc = <&tcsrcc>;
		qcom,videocc = <&videocc>;
		clocks = <&rpmhcc RPMH_CXO_CLK>,
			 <&camcc 0>,
			 <&dispcc 0>,
			 <&gcc 0>,
			 <&gpucc 0>,
			 <&tcsrcc 0>,
			 <&videocc 0>;
		clock-names = "xo_clk_src",
			      "camcc",
			      "dispcc",
			      "gcc",
			      "gpucc",
			      "tcsrcc",
			      "videocc";
		#clock-cells = <1>;
	};

	qcom_tzlog: tz-log@146AA720 {
		compatible = "qcom,tz-log";
		reg = <0x146AA720 0x3000>;
		qcom,hyplog-enabled;
		hyplog-address-offset = <0x410>;
		hyplog-size-offset = <0x414>;
	};

	qcom_cedev: qcedev@1de0000 {
		compatible = "qcom,qcedev";
		reg = <0x1de0000 0x20000>,
			<0x1dc4000 0x28000>;
		reg-names = "crypto-base","crypto-bam-base";
		interrupts = <GIC_SPI 272 IRQ_TYPE_LEVEL_HIGH>;
		qcom,bam-pipe-pair = <2>;
		qcom,offload-ops-support;
		qcom,bam-pipe-offload-cpb-hlos = <1>;
		qcom,bam-pipe-offload-hlos-cpb = <3>;
		qcom,bam-pipe-offload-hlos-hlos = <4>;
		qcom,ce-hw-instance = <0>;
		qcom,ce-device = <0>;
		qcom,ce-hw-shared;
		qcom,bam-ee = <0>;
		qcom,smmu-s1-enable;
		qcom,no-clock-support;
		interconnect-names = "data_path";
		interconnects = <&aggre2_noc MASTER_CRYPTO &mc_virt SLAVE_EBI1>;
		iommus = <&apps_smmu 0x0480 0x0>,
			<&apps_smmu 0x0481 0x0>;
		qcom,iommu-dma = "atomic";
		dma-coherent;

		qcom_cedev_ns_cb {
			compatible = "qcom,qcedev,context-bank";
			label = "ns_context";
			iommus = <&apps_smmu 0x0481 0x0>;
			dma-coherent;
		};

		qcom_cedev_s_cb {
			compatible = "qcom,qcedev,context-bank";
			label = "secure_context";
			iommus = <&apps_smmu 0x0483 0x0>;
			qcom,iommu-vmid = <0x9>;
			qcom,secure-context-bank;
			dma-coherent;
		};
	};

	qcom_rng: qrng@10c3000 {
		compatible = "qcom,msm-rng";
		reg = <0x10c3000 0x1000>;
		qcom,no-qrng-config;
		qcom,no-clock-support;
	};

	cpu_pmu: cpu-pmu {
		compatible = "arm,armv8-pmuv3";
		interrupts = <GIC_PPI 7 IRQ_TYPE_LEVEL_LOW>;
	};

	vendor_hooks: qcom,cpu-vendor-hooks {
		compatible = "qcom,cpu-vendor-hooks";
	};

	qcom,chd {
		compatible = "qcom,core-hang-detect";
		label = "core";
		qcom,chd-percpu-info = <&CPU0 0x17800058 0x17800060>,
					<&CPU1 0x17810058 0x17810060>,
					<&CPU2 0x17820058 0x17820060>,
					<&CPU3 0x17830058 0x17830060>,
					<&CPU4 0x17840058 0x17840060>,
					<&CPU5 0x17850058 0x17850060>,
					<&CPU6 0x17860058 0x17860060>,
					<&CPU7 0x17870058 0x17870060>;
	};

	qcom,rmtfs_sharedmem@0 {
		compatible = "qcom,sharedmem-uio";
		reg = <0x0 0x280000>;
		reg-names = "rmtfs";
		qcom,client-id = <0x00000001>;
	};

	ufsphy_mem: ufsphy_mem@1d80000 {
		reg = <0x1d80000 0x2000>;
		reg-names = "phy_mem";
		#phy-cells = <0>;

		lanes-per-direction = <2>;
		clock-names = "ref_clk_src",
			"ref_aux_clk", "qref_clk",
			"rx_sym0_mux_clk", "rx_sym1_mux_clk", "tx_sym0_mux_clk",
			"rx_sym0_phy_clk", "rx_sym1_phy_clk", "tx_sym0_phy_clk";
		clocks = <&rpmhcc RPMH_CXO_CLK>,
			<&gcc GCC_UFS_PHY_PHY_AUX_CLK>,
			<&tcsrcc TCSR_UFS_CLKREF_EN>,
			<&gcc GCC_UFS_PHY_RX_SYMBOL_0_CLK_SRC>,
			<&gcc GCC_UFS_PHY_RX_SYMBOL_1_CLK_SRC>,
			<&gcc GCC_UFS_PHY_TX_SYMBOL_0_CLK_SRC>,
			<&ufs_phy_rx_symbol_0_clk>,
			<&ufs_phy_rx_symbol_1_clk>,
			<&ufs_phy_tx_symbol_0_clk>;
		resets = <&ufshc_mem 0>;
		status = "disabled";
	};

	ufshc_mem: ufshc@1d84000 {
		compatible = "qcom,ufshc";
		reg = <0x1d84000 0x3000>,
		<0x1d88000 0x8000>,
		<0x1d90000 0x9000>;
		reg-names = "ufs_mem", "ufs_ice", "ufs_ice_hwkm";
		interrupts = <GIC_SPI 265 IRQ_TYPE_LEVEL_HIGH>;
		phys = <&ufsphy_mem>;
		phy-names = "ufsphy";
		#reset-cells = <1>;

		qcom,dynamic-irq-affinity;
		lanes-per-direction = <2>;
		dev-ref-clk-freq = <0>; /* 19.2 MHz */
		clock-names =
			"core_clk",
			"bus_aggr_clk",
			"iface_clk",
			"core_clk_unipro",
			"core_clk_ice",
			"ref_clk",
			"tx_lane0_sync_clk",
			"rx_lane0_sync_clk",
			"rx_lane1_sync_clk";
		clocks =
			<&gcc GCC_UFS_PHY_AXI_CLK>,
			<&gcc GCC_AGGRE_UFS_PHY_AXI_CLK>,
			<&gcc GCC_UFS_PHY_AHB_CLK>,
			<&gcc GCC_UFS_PHY_UNIPRO_CORE_CLK>,
			<&gcc GCC_UFS_PHY_ICE_CORE_CLK>,
			<&rpmhcc RPMH_LN_BB_CLK3>,
			<&gcc GCC_UFS_PHY_TX_SYMBOL_0_CLK>,
			<&gcc GCC_UFS_PHY_RX_SYMBOL_0_CLK>,
			<&gcc GCC_UFS_PHY_RX_SYMBOL_1_CLK>;
		freq-table-hz =
			<75000000 300000000>,
			<0 0>,
			<0 0>,
			<75000000 300000000>,
			<100000000 403000000>,
			<0 0>,
			<0 0>,
			<0 0>,
			<0 0>;

		interconnects = <&aggre1_noc MASTER_UFS_MEM &mc_virt SLAVE_EBI1>,
			<&gem_noc MASTER_APPSS_PROC &config_noc SLAVE_UFS_MEM_CFG>;
		interconnect-names = "ufs-ddr", "cpu-ufs";

		qcom,ufs-bus-bw,name = "ufshc_mem";
		qcom,ufs-bus-bw,num-cases = <26>;
		qcom,ufs-bus-bw,num-paths = <2>;
		qcom,ufs-bus-bw,vectors-KBps =
		/*
		 * During HS G3 UFS runs at nominal voltage corner, vote
		 * higher bandwidth to push other buses in the data path
		 * to run at nominal to achieve max throughput.
		 * 4GBps pushes BIMC to run at nominal.
		 * 200MBps pushes CNOC to run at nominal.
		 * Vote for half of this bandwidth for HS G3 1-lane.
		 * For max bandwidth, vote high enough to push the buses
		 * to run in turbo voltage corner.
		 */
		<0 0>, <0 0>,          /* No vote */
		<922 0>, <1000 0>,     /* PWM G1 */
		<1844 0>, <1000 0>,    /* PWM G2 */
		<3688 0>, <1000 0>,    /* PWM G3 */
		<7376 0>, <1000 0>,    /* PWM G4 */
		<1844 0>, <1000 0>,    /* PWM G1 L2 */
		<3688 0>, <1000 0>,    /* PWM G2 L2 */
		<7376 0>, <1000 0>,    /* PWM G3 L2 */
		<14752 0>, <1000 0>,   /* PWM G4 L2 */
		<127796 0>, <1000 0>,  /* HS G1 RA */
		<255591 0>, <1000 0>,  /* HS G2 RA */
		<1492582 0>, <102400 0>,  /* HS G3 RA */
		<2915200 0>, <204800 0>,  /* HS G4 RA */
		<255591 0>, <1000 0>,  /* HS G1 RA L2 */
		<511181 0>, <1000 0>,  /* HS G2 RA L2 */
		<1492582 0>, <204800 0>, /* HS G3 RA L2 */
		<2915200 0>, <409600 0>, /* HS G4 RA L2 */
		<149422 0>, <1000 0>,  /* HS G1 RB */
		<298189 0>, <1000 0>,  /* HS G2 RB */
		<1492582 0>, <102400 0>,  /* HS G3 RB */
		<2915200 0>, <204800 0>,  /* HS G4 RB */
		<298189 0>, <1000 0>,  /* HS G1 RB L2 */
		<596378 0>, <1000 0>,  /* HS G2 RB L2 */
		/* As UFS working in HS G3 RB L2 mode, aggregated
		 * bandwidth (AB) should take care of providing
		 * optimum throughput requested. However, as tested,
		 * in order to scale up CNOC clock, instantaneous
		 * bindwidth (IB) needs to be given a proper value too.
		 */
		<1492582 0>, <204800 409600>, /* HS G3 RB L2 KBPs */
		<2915200 0>, <409600 409600>, /* HS G4 RB L2 */
		<7643136 0>, <819200 0>;      /* Max. bandwidth */

		qcom,bus-vector-names = "MIN",
		"PWM_G1_L1", "PWM_G2_L1", "PWM_G3_L1", "PWM_G4_L1",
		"PWM_G1_L2", "PWM_G2_L2", "PWM_G3_L2", "PWM_G4_L2",
		"HS_RA_G1_L1", "HS_RA_G2_L1", "HS_RA_G3_L1", "HS_RA_G4_L1",
		"HS_RA_G1_L2", "HS_RA_G2_L2", "HS_RA_G3_L2", "HS_RA_G4_L2",
		"HS_RB_G1_L1", "HS_RB_G2_L1", "HS_RB_G3_L1", "HS_RB_G4_L1",
		"HS_RB_G1_L2", "HS_RB_G2_L2", "HS_RB_G3_L2", "HS_RB_G4_L2",
		"MAX";

		reset-gpios = <&tlmm 167 GPIO_ACTIVE_LOW>;
		resets = <&gcc GCC_UFS_PHY_BCR>;
		reset-names = "rst";

		iommus = <&apps_smmu 0x20 0x0>;
		qcom,iommu-dma = "fastmap";
		dma-coherent;

		qcom,iommu-dma-addr-pool = <0x40000000 0x40000000>;
		qcom,iommu-geometry = <0x40000000 0x40000000>;

		status = "disabled";

		qos0 {
			vote = <44>;
			perf;
		};

		qos1 {
			vote = <44>;
		};

	};

	qcom,msm-imem@146aa000 {
		compatible = "qcom,msm-imem";
		reg = <0x146aa000 0x1000>;
		ranges = <0x0 0x146aa000 0x1000>;
		#address-cells = <1>;
		#size-cells = <1>;

		mem_dump_table@10 {
			compatible = "qcom,msm-imem-mem_dump_table";
			reg = <0x10 0x8>;
		};

		restart_reason@65c {
			compatible = "qcom,msm-imem-restart_reason";
			reg = <0x65c 0x4>;
		};

		dload_type@1c {
			compatible = "qcom,msm-imem-dload-type";
			reg = <0x1c 0x4>;
		};

		boot_stats@6b0 {
			compatible = "qcom,msm-imem-boot_stats";
			reg = <0x6b0 0x20>;
		};

		kaslr_offset@6d0 {
			compatible = "qcom,msm-imem-kaslr_offset";
			reg = <0x6d0 0xc>;
		};

		pil@94c {
			compatible = "qcom,pil-reloc-info";
			reg = <0x94c 0xc8>;
		};

		pil@6dc {
			compatible = "qcom,msm-imem-pil-disable-timeout";
			reg = <0x6dc 0x4>;
		};

		diag_dload@c8 {
			compatible = "qcom,msm-imem-diag-dload";
			reg = <0xc8 0xc8>;
		};
	};

	qcom,mpm2-sleep-counter@c221000 {
		compatible = "qcom,mpm2-sleep-counter";
		reg = <0xc221000 0x1000>;
		clock-frequency = <32768>;
	};

	dload_mode {
		compatible = "qcom,dload-mode";
	};

	eud: qcom,msm-eud@88e0000 {
		compatible = "qcom,msm-eud";
		interrupt-names = "eud_irq";
		interrupt-parent = <&pdc>;
		interrupts = <11 IRQ_TYPE_LEVEL_HIGH>;
		reg = <0x088E0000 0x2000>,
			<0x088E2000 0x1000>;
		reg-names = "eud_base", "eud_mode_mgr2";
		qcom,secure-eud-en;
		status = "ok";
	};

	logbuf: qcom,logbuf-vendor-hooks {
		compatible = "qcom,logbuf-vendor-hooks";
	};

	qcom,sps {
		compatible = "qcom,msm-sps-4k";
		qcom,pipe-attr-ee;
	};

	qcom,msm-rtb {
		compatible = "qcom,msm-rtb";
		qcom,rtb-size = <0x100000>;
	};

	qcom,secure-buffer {
		compatible = "qcom,secure-buffer";
		qcom,vmid-cp-camera-preview-ro;
	};

	qcom,mem-buf {
		compatible = "qcom,mem-buf";
		qcom,mem-buf-capabilities = "supplier";
		qcom,vmid = <3>;
	};

	qcom,mem-buf-msgq {
		compatible = "qcom,mem-buf-msgq";
	};

	qcom,memshare {
		compatible = "qcom,memshare";

		qcom,client_1 {
			compatible = "qcom,memshare-peripheral";
			qcom,peripheral-size = <0x0>;
			qcom,client-id = <0>;
			qcom,allocate-boot-time;
			label = "modem";
		};

		qcom,client_2 {
			compatible = "qcom,memshare-peripheral";
			qcom,peripheral-size = <0x0>;
			qcom,client-id = <2>;
			label = "modem";
		};

		mem_client_3: qcom,client_3 {
			compatible = "qcom,memshare-peripheral";
			qcom,peripheral-size = <0x500000>;
			qcom,client-id = <1>;
			qcom,allocate-on-request;
			label = "modem";
		};
	};

	qfprom: qfprom@221c8000 {
		compatible = "qcom,crow-qfprom", "qcom,qfprom";
		reg = <0x221c8000 0x1000>;
		#address-cells = <1>;
		#size-cells = <1>;
		read-only;
		ranges;

		adsp_variant: adsp_variant@128 {
			reg = <0x128 0x4>;
			bits = <25 6>;
		};

		gpu_gaming_bin: gpu_gaming_bin@133 {
			reg = <0x133 0x1>;
			bits = <7 1>;
		};

		feat_conf13: feat_conf13@0134 {
			reg = <0x0134 0x4>;
		};

		gpu_speed_bin: gpu_speed_bin@13a {
			reg = <0x13a 0x2>;
			bits = <2 9>;
		};
	};

	qfprom_sys: qfprom@0 {
		compatible = "qcom,qfprom-sys";

		nvmem-cells = <&adsp_variant>,
				<&feat_conf13>;
		nvmem-cell-names = "adsp_variant",
				"feat_conf13";
	};

	wpss_pas: remoteproc-wpss@9f700000 {
		compatible = "qcom,crow-wpss-pas";
		reg = <0x9f700000 0x10000>;
		status = "ok";

		memory-region = <&wpss_moselle_mem>;
		firmware-name = "qca6750/wpss.mdt";

		clocks = <&rpmhcc RPMH_CXO_CLK>;
		clock-names = "xo";

		cx-supply = <&VDD_CX_LEVEL>;
		cx-uV-uA = <RPMH_REGULATOR_LEVEL_TURBO 100000>;
		mx-supply = <&VDD_MXA_LEVEL>;
		mx-uV-uA = <RPMH_REGULATOR_LEVEL_TURBO 100000>;
		reg-names = "cx","mx";

		qcom,signal-aop;
		qcom,qmp = <&aoss_qmp>;

		/* Inputs from wpss */
		interrupts-extended = <&intc GIC_SPI 579 IRQ_TYPE_EDGE_RISING>,
				      <&wpss_smp2p_in 0 0>,
				      <&wpss_smp2p_in 2 0>,
				      <&wpss_smp2p_in 1 0>,
				      <&wpss_smp2p_in 3 0>,
				      <&wpss_smp2p_in 7 0>;

		interrupt-names = "wdog",
				   "fatal",
				   "handover",
				   "ready",
				   "stop-ack",
				   "shutdown-ack";

		/* Outputs to wpss */
		qcom,smem-states = <&wpss_smp2p_out 0>;
		qcom,smem-state-names = "stop";

		glink-edge {
			qcom,remote-pid = <13>;
			transport = "smem";
			mboxes = <&ipcc_mproc IPCC_CLIENT_WPSS
				  IPCC_MPROC_SIGNAL_GLINK_QMP>;
			mbox-names = "wpss_smem";
			interrupt-parent = <&ipcc_mproc>;
			interrupts = <IPCC_CLIENT_WPSS
					  IPCC_MPROC_SIGNAL_GLINK_QMP
					  IRQ_TYPE_EDGE_RISING>;

			label = "wpss";
			qcom,glink-label = "wpss";

			qcom,wpss_qrtr {
				qcom,glink-channels = "IPCRTR";
				qcom,intents = <0x800  5
						0x2000 3
						0x4400 2>;
			};

		};
	};

	adsp_pas: remoteproc-adsp@03000000 {
		compatible = "qcom,crow-adsp-pas";
		reg = <0x03000000 0x10000>;
		status = "ok";

		cx-supply = <&VDD_LPI_CX_LEVEL>;
		cx-uV-uA = <RPMH_REGULATOR_LEVEL_TURBO 0>;
		mx-supply = <&VDD_LPI_MX_LEVEL>;
		mx-uV-uA = <RPMH_REGULATOR_LEVEL_TURBO 0>;
		reg-names = "cx", "mx";

		clocks = <&rpmhcc RPMH_CXO_CLK>;
		clock-names = "xo";

		qcom,signal-aop;
		qcom,qmp = <&aoss_qmp>;

		interconnects = <&lpass_ag_noc MASTER_LPASS_PROC &mc_virt SLAVE_EBI1>,
			<&aggre2_noc MASTER_CRYPTO &mc_virt SLAVE_EBI1>;
		interconnect-names = "rproc_ddr", "crypto_ddr";

		memory-region = <&adsp_mem &q6_adsp_dtb_mem>;

		/* Inputs from ssc */
		interrupts-extended = <&pdc 6 IRQ_TYPE_EDGE_RISING>,
					<&adsp_smp2p_in 0 0>,
					<&adsp_smp2p_in 2 0>,
					<&adsp_smp2p_in 1 0>,
					<&adsp_smp2p_in 3 0>,
					<&adsp_smp2p_in 7 0>;

		interrupt-names = "wdog",
				"fatal",
				"handover",
				"ready",
				"stop-ack",
				"shutdown-ack";

		/* Outputs to turing */
		qcom,smem-states = <&adsp_smp2p_out 0>;
		qcom,smem-state-names = "stop";

		glink_edge: glink-edge {
			qcom,remote-pid = <2>;
			transport = "smem";
			mboxes = <&ipcc_mproc IPCC_CLIENT_LPASS
				  IPCC_MPROC_SIGNAL_GLINK_QMP>;
			mbox-names = "adsp_smem";
			interrupt-parent = <&ipcc_mproc>;
			interrupts = <IPCC_CLIENT_LPASS
				      IPCC_MPROC_SIGNAL_GLINK_QMP
				      IRQ_TYPE_EDGE_RISING>;

			label = "adsp";
			qcom,glink-label = "lpass";

			qcom,adsp_qrtr {
				qcom,glink-channels = "IPCRTR";
				qcom,intents = <0x800  5
						0x2000 3
						0x4400 2>;

				qcom,no-wake-svc = <0x190>;
			};

			qcom,msm_fastrpc_rpmsg {
				compatible = "qcom,msm-fastrpc-rpmsg";
				qcom,glink-channels = "fastrpcglink-apps-dsp";
				qcom,intents = <0x64 64>;
			};

			qcom,msm_adspsleepmon_rpmsg {
				compatible = "qcom,msm-adspsleepmon-rpmsg";
				qcom,glink-channels = "sleepmonglink-apps-adsp";
				qcom,intents = <0x1000 8>;
			};

			qcom,pmic_glink_rpmsg {
				qcom,glink-channels = "PMIC_RTR_ADSP_APPS";
			};

			qcom,pmic_glink_log_rpmsg {
				qcom,glink-channels = "PMIC_LOGS_ADSP_APPS";
				qcom,intents = <0x800 5
						0xc00 3
						0x2000 1>;
			};
		};
	};

	cdsp_pas: remoteproc-cdsp@32300000 {
		compatible = "qcom,crow-cdsp-pas";
		reg = <0x32300000 0x10000>;
		status = "ok";

		cx-supply = <&VDD_CX_LEVEL>;
		cx-uV-uA = <RPMH_REGULATOR_LEVEL_TURBO 100000>;
		mx-supply = <&VDD_MXC_LEVEL>;
		mx-uV-uA = <RPMH_REGULATOR_LEVEL_TURBO 100000>;
		reg-names = "cx","mx";

		clocks = <&rpmhcc RPMH_CXO_CLK>;
		clock-names = "xo";

		qcom,signal-aop;
		qcom,qmp = <&aoss_qmp>;

		interconnects = <&nsp_noc MASTER_CDSP_PROC &mc_virt SLAVE_EBI1>,
			<&aggre2_noc MASTER_CRYPTO &mc_virt SLAVE_EBI1>;
		interconnect-names = "rproc_ddr", "crypto_ddr";

		memory-region = <&cdsp_mem &q6_cdsp_dtb_mem>;

		/* Inputs from turing */
		interrupts-extended = <&intc GIC_SPI 578 IRQ_TYPE_EDGE_RISING>,
					<&cdsp_smp2p_in 0 0>,
					<&cdsp_smp2p_in 2 0>,
					<&cdsp_smp2p_in 1 0>,
					<&cdsp_smp2p_in 3 0>,
					<&cdsp_smp2p_in 7 0>;

		interrupt-names = "wdog",
				"fatal",
				"handover",
				"ready",
				"stop-ack",
				"shutdown-ack";

		/* Outputs to turing */
		qcom,smem-states = <&cdsp_smp2p_out 0>;
		qcom,smem-state-names = "stop";

		glink-edge {
			qcom,remote-pid = <5>;
			transport = "smem";
			mboxes = <&ipcc_mproc IPCC_CLIENT_CDSP
				  IPCC_MPROC_SIGNAL_GLINK_QMP>;
			mbox-names = "cdsp_smem";
			interrupt-parent = <&ipcc_mproc>;
			interrupts = <IPCC_CLIENT_CDSP
				      IPCC_MPROC_SIGNAL_GLINK_QMP
				      IRQ_TYPE_EDGE_RISING>;

			label = "cdsp";
			qcom,glink-label = "cdsp";

			qcom,cdsp_qrtr {
				qcom,glink-channels = "IPCRTR";
				qcom,intents = <0x800  5
						0x2000 3
						0x4400 2>;
			};

			qcom,msm_fastrpc_rpmsg {
				compatible = "qcom,msm-fastrpc-rpmsg";
				qcom,glink-channels = "fastrpcglink-apps-dsp";
				qcom,intents = <0x64 64>;
			};

			qcom,msm_cdsprm_rpmsg {
				compatible = "qcom,msm-cdsprm-rpmsg";
				qcom,glink-channels = "cdsprmglink-apps-dsp";
				qcom,intents = <0x20 12>;

				msm_cdsp_rm: qcom,msm_cdsp_rm {
					compatible = "qcom,msm-cdsp-rm";
					qcom,qos-cores = <0 1 2 3>;
					qcom,qos-latency-us = <70>;
					qcom,qos-maxhold-ms = <20>;
				};
			};
		};
	};

	modem_pas: remoteproc-mss@04080000 {
		compatible = "qcom,crow-modem-pas";
		reg = <0x4080000 0x10000>;
		status = "ok";

		cx-supply = <&VDD_CX_LEVEL>;
		cx-uV-uA = <RPMH_REGULATOR_LEVEL_TURBO 100000>;
		mx-supply = <&VDD_MODEM_LEVEL>;
		mx-uV-uA = <RPMH_REGULATOR_LEVEL_NOM_L1 100000>;
		reg-names = "cx", "mx";

		clocks = <&rpmhcc RPMH_CXO_CLK>;
		clock-names = "xo";

		qcom,signal-aop;
		qcom,qmp = <&aoss_qmp>;

		interconnects = <&mc_virt MASTER_LLCC &mc_virt SLAVE_EBI1>,
			<&aggre2_noc MASTER_CRYPTO &mc_virt SLAVE_EBI1>;
		interconnect-names = "rproc_ddr", "crypto_ddr";

		memory-region = <&mpss_mem &q6_mpss_dtb_mem &system_cma>;

		/* Inputs from mss */
		interrupts-extended = <&intc GIC_SPI 264 IRQ_TYPE_EDGE_RISING>,
					<&modem_smp2p_in 0 0>,
					<&modem_smp2p_in 2 0>,
					<&modem_smp2p_in 1 0>,
					<&modem_smp2p_in 3 0>,
					<&modem_smp2p_in 7 0>;

		interrupt-names = "wdog",
				"fatal",
				"handover",
				"ready",
				"stop-ack",
				"shutdown-ack";

		/* Outputs to mss */
		qcom,smem-states = <&modem_smp2p_out 0>;
		qcom,smem-state-names = "stop";

		glink-edge {
			qcom,remote-pid = <1>;
			transport = "smem";
			mboxes = <&ipcc_mproc IPCC_CLIENT_MPSS
				  IPCC_MPROC_SIGNAL_GLINK_QMP>;
			mbox-names = "mpss_smem";
			interrupt-parent = <&ipcc_mproc>;
			interrupts = <IPCC_CLIENT_MPSS
				      IPCC_MPROC_SIGNAL_GLINK_QMP
				      IRQ_TYPE_EDGE_RISING>;

			label = "modem";
			qcom,glink-label = "mpss";

			qcom,modem_qrtr {
				qcom,glink-channels = "IPCRTR";
				qcom,low-latency;
				qcom,intents = <0x800  5
						0x2000 3
						0x4400 2>;
			};

			qcom,modem_ds {
				qcom,glink-channels = "DS";
				qcom,intents = <0x4000 0x2>;
			};
		};
	};

	llcc_pmu: llcc-pmu@24095000 {
		compatible = "qcom,llcc-pmu-ver2";
		reg = <0x24095000 0x300>;
		reg-names = "lagg-base";
	};

	qcom_pmu: qcom,pmu {
		compatible = "qcom,pmu";
		qcom,long-counter;
		qcom,pmu-events-tbl =
			< 0x0008 0xFF 0x02 0xFF >,
			< 0x0011 0xFF 0x01 0xFF >,
			< 0x0017 0xFF 0xFF 0xFF >,
			< 0x0037 0xFF 0xFF 0xFF >,
			< 0x1000 0xFF 0xFF 0xFF >,
			< 0x4005 0xFF 0x03 0xFF >;
	};

	ddr_freq_table: ddr-freq-table {
		ddr4 {
			qcom,ddr-type = <7>;
			qcom,freq-tbl =
				<  547200 >,
				<  768000 >,
				< 1017600 >,
				< 1353600 >,
				< 1555200 >,
				< 1708800 >,
				< 2092800 >,
				< 2133000 >;
		};

		ddr5 {
			qcom,ddr-type = <8>;
			qcom,freq-tbl =
				<  547200 >,
				<  768000 >,
				< 1555200 >,
				< 1708800 >,
				< 2092800 >,
				< 2736000 >,
				< 3196800 >;
		};
	};

	llcc_freq_table: llcc-freq-table {
		qcom,freq-tbl =
			<  300000 >,
			<  466500 >,
			<  600000 >,
			<  806000 >,
			< 1066000 >;
	};

	ddrqos_freq_table: ddrqos-freq-table {
		qcom,freq-tbl =
			< 0 >,
			< 1 >;
	};

	qcom_dcvs: qcom,dcvs {
		compatible = "qcom,dcvs";
		#address-cells = <1>;
		#size-cells = <1>;
		ranges;

		qcom_l3_dcvs_hw: l3 {
			compatible = "qcom,dcvs-hw";
			qcom,dcvs-hw-type = <2>;
			qcom,bus-width = <32>;
			reg = <0x17d90000 0x4000>, <0x17d90100 0xa0>;
			reg-names = "l3-base", "l3tbl-base";

			l3_dcvs_sp: sp {
				compatible = "qcom,dcvs-path";
				qcom,dcvs-path-type = <0>;
				qcom,shared-offset = <0x0090>;
			};
		};

		qcom_ddr_dcvs_hw: ddr {
			compatible = "qcom,dcvs-hw";
			qcom,dcvs-hw-type = <0>;
			qcom,bus-width = <4>;
			qcom,freq-tbl = <&ddr_freq_table>;

			ddr_dcvs_sp: sp {
				compatible = "qcom,dcvs-path";
				qcom,dcvs-path-type = <0>;
				interconnects = <&mc_virt MASTER_LLCC
						 &mc_virt SLAVE_EBI1>;
			};

			ddr_dcvs_fp: fp {
				compatible = "qcom,dcvs-path";
				qcom,dcvs-path-type = <1>;
				qcom,fp-voter = <&dcvs_fp>;
			};

		};

		qcom_llcc_dcvs_hw: llcc {
			compatible = "qcom,dcvs-hw";
			qcom,dcvs-hw-type = <1>;
			qcom,bus-width = <16>;
			qcom,freq-tbl = <&llcc_freq_table>;

			llcc_dcvs_sp: sp {
				compatible = "qcom,dcvs-path";
				qcom,dcvs-path-type = <0>;
				interconnects = <&gem_noc MASTER_APPSS_PROC
						 &gem_noc SLAVE_LLCC>;
			};

			llcc_dcvs_fp: fp {
				compatible = "qcom,dcvs-path";
				qcom,dcvs-path-type = <1>;
				qcom,fp-voter = <&dcvs_fp>;
			};
		};

		qcom_ddrqos_dcvs_hw: ddrqos {
			compatible = "qcom,dcvs-hw";
			qcom,dcvs-hw-type = <3>;
			qcom,bus-width = <1>;
			qcom,freq-tbl = <&ddrqos_freq_table>;

			ddrqos_dcvs_sp: sp {
				compatible = "qcom,dcvs-path";
				qcom,dcvs-path-type = <0>;
				interconnects = <&mc_virt MASTER_LLCC
						 &mc_virt SLAVE_EBI1>;
			};
		};
	};

	qcom_scmi_plh: qcom,scmi_plh {
		compatible = "qcom,scmi_plh";
	};

	qcom_memlat: qcom,memlat {
		compatible = "qcom,memlat";
		qcom,be-stall-ev = <0x4005>;
		ddr {
			compatible = "qcom,memlat-grp";
			qcom,target-dev = <&qcom_ddr_dcvs_hw>;
			qcom,sampling-path = <&ddr_dcvs_fp>;
			qcom,miss-ev = <0x1000>;

			silver {
				compatible = "qcom,memlat-mon";
				qcom,cpulist = <&CPU0 &CPU1 &CPU2 &CPU3>;
				qcom,sampling-enabled;
				ddr4-tbl {
					qcom,ddr-type = <7>;
					qcom,cpufreq-memfreq-tbl =
						< 1075200  547200 >,
						< 1555200  768000 >,
						< 1939200 1017600 >;
				};

				ddr5-tbl {
					qcom,ddr-type = <8>;
					qcom,cpufreq-memfreq-tbl =
						< 1075200  547200 >,
						< 1555200  768000 >,
						< 1939200 1555200 >;
				};
			};

			gold {
				compatible = "qcom,memlat-mon";
				qcom,cpulist = <&CPU4 &CPU5 &CPU6>;
				qcom,sampling-enabled;
				ddr4-tbl {
					qcom,ddr-type = <7>;
					qcom,cpufreq-memfreq-tbl =
						<  940800  547200 >,
						< 1113600 1017600 >,
						< 2208000 1708800 >,
						< 2400000 2092800 >;
				};

				ddr5-tbl {
					qcom,ddr-type = <8>;
					qcom,cpufreq-memfreq-tbl =
						<  940800  547200 >,
						< 1113600  768000 >,
						< 1651200 1555200 >,
						< 1804800 1708800 >,
						< 2208000 2092800 >,
						< 2400000 3196800 >;
				};
			};

			prime {
				compatible = "qcom,memlat-mon";
				qcom,cpulist = <&CPU7>;
				qcom,sampling-enabled;
				ddr4-tbl {
					qcom,ddr-type = <7>;
					qcom,cpufreq-memfreq-tbl =
						<  940800  547200 >,
						< 1267200 1017600 >,
						< 1401600 1555200 >,
						< 1804800 1708800 >,
						< 2284800 2092800 >;
				};

				ddr5-tbl {
					qcom,ddr-type = <8>;
					qcom,cpufreq-memfreq-tbl =
						<  940800  547200 >,
						< 1267200  768000 >,
						< 1401600 1555200 >,
						< 1651200 1708800 >,
						< 1804800 2092800 >,
						< 2284800 3196800 >;
				};
			};

			silver-compute {
				compatible = "qcom,memlat-mon";
				qcom,cpulist = <&CPU0 &CPU1 &CPU2 &CPU3>;
				qcom,sampling-enabled;
				qcom,compute-mon;
				ddr4-tbl {
					qcom,ddr-type = <7>;
					qcom,cpufreq-memfreq-tbl =
						< 1555200  547200 >,
						< 1804800  768000 >;
				};

				ddr5-tbl {
					qcom,ddr-type = <8>;
					qcom,cpufreq-memfreq-tbl =
						< 1555200  547200 >,
						< 1804800  768000 >;
				};
			};

			gold-compute {
				compatible = "qcom,memlat-mon";
				qcom,cpulist = <&CPU4 &CPU5 &CPU6 &CPU7>;
				qcom,sampling-enabled;
				qcom,compute-mon;
				ddr4-tbl {
					qcom,ddr-type = <7>;
					qcom,cpufreq-memfreq-tbl =
						<  940800  547200 >,
						< 1113600  768000 >,
						< 1651200 1017600 >,
						< 2208000 1708800 >,
						< 2400000 2092800 >;
				};

				ddr5-tbl {
					qcom,ddr-type = <8>;
					qcom,cpufreq-memfreq-tbl =
						<  940800  547200 >,
						< 1113600  768000 >,
						< 1651200 1555200 >,
						< 1804800 1708800 >,
						< 2208000 2092800 >,
						< 2400000 3196800 >;
				};
			};

			prime-latfloor {
				compatible = "qcom,memlat-mon";
				qcom,cpulist = <&CPU7>;
				qcom,sampling-enabled;
				ddr4-tbl {
					qcom,ddr-type = <7>;
					qcom,cpufreq-memfreq-tbl =
						< 2284800  547200 >,
						< 2592000 2092800 >;
				};

				ddr5-tbl {
					qcom,ddr-type = <8>;
					qcom,cpufreq-memfreq-tbl =
						< 2284800  547200 >,
						< 2592000 3196800 >;
				};
			};
		};

		llcc {
			compatible = "qcom,memlat-grp";
			qcom,target-dev = <&qcom_llcc_dcvs_hw>;
			qcom,sampling-path = <&llcc_dcvs_fp>;
			qcom,miss-ev = <0x37>;

			silver {
				compatible = "qcom,memlat-mon";
				qcom,cpulist = <&CPU0 &CPU1 &CPU2 &CPU3>;
				qcom,cpufreq-memfreq-tbl =
					< 1075200  300000 >,
					< 1555200  466500 >,
					< 1958400  600000 >;
				qcom,sampling-enabled;
			};

			gold {
				compatible = "qcom,memlat-mon";
				qcom,cpulist = <&CPU4 &CPU5 &CPU6 &CPU7>;
				qcom,cpufreq-memfreq-tbl =
					<  652800   300000 >,
					< 1113600   466500 >,
					< 1267200   600000 >,
					< 2208000   806000 >,
					< 2400000  1066000 >;
				qcom,sampling-enabled;
			};

			gold-compute {
				compatible = "qcom,memlat-mon";
				qcom,cpulist = <&CPU4 &CPU5 &CPU6 &CPU7>;
				qcom,cpufreq-memfreq-tbl =
					< 2054400  300000 >,
					< 2400000  600000 >;
				qcom,sampling-enabled;
				qcom,compute-mon;
			};

			prime-latfloor {
				compatible = "qcom,memlat-mon";
				qcom,cpulist = <&CPU7>;
				qcom,cpufreq-memfreq-tbl =
					< 2284800   300000 >,
					< 2592000  1066000 >;
				qcom,sampling-enabled;
			};
		};

		l3 {
			compatible = "qcom,memlat-grp";
			qcom,target-dev = <&qcom_l3_dcvs_hw>;
			qcom,sampling-path = <&l3_dcvs_sp>;
			qcom,miss-ev = <0x17>;

			silver {
				compatible = "qcom,memlat-mon";
				qcom,cpulist = <&CPU0 &CPU1 &CPU2 &CPU3>;
				qcom,cpufreq-memfreq-tbl =
					<  441600  384000 >,
					<  614400  595200 >,
					<  806400  710400 >,
					<  902400  825600 >,
					< 1075200  998400 >,
					< 1228800 1132800 >,
					< 1363200 1286400 >,
					< 1555200 1382400 >,
					< 1689600 1478400 >,
					< 1804800 1651200 >,
					< 1939200 1747200 >;
				qcom,sampling-enabled;
			};

			gold {
				compatible = "qcom,memlat-mon";
				qcom,cpulist = <&CPU4 &CPU5 &CPU6>;
				qcom,cpufreq-memfreq-tbl =
					<  300000  384000 >,
					<  940800  595200 >,
					< 1113600  710400 >,
					< 1267200  998400 >,
					< 1516800 1132800 >,
					< 1804800 1382400 >,
					< 2054400 1478400 >,
					< 2208000 1651200 >,
					< 2400000 1747200 >;
				qcom,sampling-enabled;
			};

			prime {
				compatible = "qcom,memlat-mon";
				qcom,cpulist = <&CPU7>;
				qcom,cpufreq-memfreq-tbl =
					<  300000  384000 >,
					<  940800  710400 >,
					< 1171200  998400 >,
					< 1267200 1132800 >,
					< 1516800 1382400 >,
					< 2054400 1651200 >,
					< 2592000 1747200 >;
				qcom,sampling-enabled;
			};

			gold-compute {
				compatible = "qcom,memlat-mon";
				qcom,cpulist = <&CPU4 &CPU5 &CPU6 &CPU7>;
				qcom,cpufreq-memfreq-tbl =
					< 1516800  384000 >,
					< 2400000 1286400 >;
				qcom,sampling-enabled;
				qcom,compute-mon;
			};
		};

		ddrqos {
			compatible = "qcom,memlat-grp";
			qcom,target-dev = <&qcom_ddrqos_dcvs_hw>;
			qcom,sampling-path = <&ddrqos_dcvs_sp>;
			qcom,miss-ev = <0x1000>;

			ddrqos_gold_lat: gold {
				compatible = "qcom,memlat-mon";
				qcom,cpulist = <&CPU4 &CPU5 &CPU6 &CPU7>;
				qcom,cpufreq-memfreq-tbl =
					< 1881600 0 >,
					< 2400000 1 >;
				qcom,sampling-enabled;
			};

			ddrqos_prime_latfloor: prime-latfloor {
				compatible = "qcom,memlat-mon";
				qcom,cpulist = <&CPU7>;
				qcom,cpufreq-memfreq-tbl =
					< 2054400 0 >,
					< 2592000 1 >;
				qcom,sampling-enabled;
			};
		};
	};

	cache-controller@25000000 {
		compatible = "qcom,crow-llcc", "qcom,llcc-v50";
		reg = <0x25000000 0x400000> , <0x25800000 0x200000>;
		reg-names = "llcc_base", "llcc_broadcast_base";
		interrupts = <GIC_SPI 266 IRQ_TYPE_LEVEL_HIGH>;
		cap-based-alloc-and-pwr-collapse;

		llcc-perfmon {
			compatible = "qcom,llcc-perfmon";
			clocks = <&aoss_qmp QDSS_CLK>;
			clock-names = "qdss_clk";
		};
	};

	mini_dump_node {
		compatible = "qcom,minidump";
		status = "ok";
	};

	va_mini_dump {
		compatible = "qcom,va-minidump";
		memory-region = <&va_md_mem>;
		status = "ok";
	};

	msm_gpu: qcom,kgsl-3d0@3d00000 { };

	qrtr-gunyah-tvm {
		compatible = "qcom,qrtr-gunyah";
		qcom,master;
		gunyah-label = <3>;
		peer-name = <2>;
		shared-buffer = <&trust_ui_vm_qrtr>;
	};

	qrtr-gunyah-oemvm {
		compatible = "qcom,qrtr-gunyah";
		qcom,master;
		gunyah-label = <8>;
		peer-name = <4>;
	};

	trust_ui_vm: qcom,trust_ui_vm@0xf78f8000 {
		reg = <0xf78f8000 0x108000>;
		vm_name = "trustedvm";
		shared-buffers = <&trust_ui_vm_vblk0_ring &trust_ui_vm_vblk1_ring &trust_ui_vm_swiotlb>;
	};

	oem_vm: qcom,oem_vm@f7afc000 {
		reg = <0xf7afc000 0x104000>;
		vm_name = "oemvm";
		shared-buffers = <&oem_vm_vblk0_ring &oem_vm_swiotlb>;
	};

	trust_ui_vm_virt_be0: trust_ui_vm_virt_be0@11 {
		qcom,vm = <&trust_ui_vm>;
		qcom,label = <0x11>;
	};

	trust_ui_vm_virt_be1: trust_ui_vm_virt_be1@10 {
		qcom,vm = <&trust_ui_vm>;
		qcom,label = <0x10>;
	};

	gh-secure-vm-loader@0 {
		compatible = "qcom,gh-secure-vm-loader";
		qcom,pas-id = <28>;
		qcom,vmid = <45>;
		qcom,firmware-name = "trustedvm";
		qcom,keep-running;
		memory-region = <&trust_ui_vm_mem>;
		virtio-backends = <&trust_ui_vm_virt_be0 &trust_ui_vm_virt_be1>;
	};

	oem_vm_virt_be0: oem_vm_virt_be0@13 {
		qcom,vm = <&oem_vm>;
		qcom,label = <0x13>;
	};

	gh-secure-vm-loader@1 {
		compatible = "qcom,gh-secure-vm-loader";
		qcom,pas-id = <34>;
		qcom,vmid = <49>;
		qcom,firmware-name = "oemvm";
		memory-region = <&oem_vm_mem>;
		virtio-backends = <&oem_vm_virt_be0>;
	};

	gh-secure-vm-loader@2 {
		compatible = "qcom,gh-secure-vm-loader";
		qcom,pas-id = <35>;
		qcom,vmid = <50>;
		qcom,firmware-name = "cpusys_vm";
		memory-region = <&cpusys_vm_mem>;
		ext-region = <&chipinfo_mem>;
		ext-label = <0x7>;
	};

	dmesg-dump {
		compatible = "qcom,dmesg-dump";
		qcom,primary-vm;
		gunyah-label = <7>;
		peer-name = <2>;
		shared-buffer = <&trust_ui_vm_dump>;
	};

	tlmm-vm-mem-access {
		compatible = "qcom,tlmm-vm-mem-access";
		qcom,master;
		tlmm-vm-gpio-list = <&tlmm 0 0 &tlmm 1 0 &tlmm 2 0 &tlmm 3 0
				&tlmm 21 0 &tlmm 28 0 &tlmm 122 0 &tlmm 29 0>;
	};

	tlmm-vm-test {
		compatible = "qcom,tlmm-vm-test";
		qcom,master;
		tlmm-vm-gpio-list = <&tlmm 0 0 &tlmm 1 0 &tlmm 2 0 &tlmm 3 0
				&tlmm 21 0 &tlmm 28 0 &tlmm 122 0 &tlmm 29 0>;
	};

	qcom,test-dbl {
		compatible = "qcom,gh-dbl";
		qcom,label = <0x4>;
	};

	qcom,gh-qtimer@17425000 {
		compatible = "qcom,gh-qtmr";
		reg = <0x17425000 0x1000>;
		reg-names = "qtmr-base";
		interrupts = <GIC_SPI 10 IRQ_TYPE_LEVEL_HIGH>;
		interrupt-names = "qcom,qtmr-intr";
		qcom,primary;
	};

	qcom,test-msgq {
		compatible = "qcom,gh-msgq-test";
		gunyah-label = <4>;
		qcom,primary;
	};

	qcom_llcc_l3_vote: qcom,llcc-l3-vote {
		qcom,target-dev = <&qcom_l3_dcvs_hw>;
		qcom,secondary-map =
			<  300000  384000 >,
			<  466500  595200 >,
			<  600000  710400 >,
			<  806000  825600 >,
			< 1066000  998400 >;
	};

	bwmon_llcc: qcom,bwmon-llcc@240B6300 {
		compatible = "qcom,bwmon4";
		reg = <0x240B6400 0x300>, <0x240B6300 0x200>;
		reg-names = "base", "global_base";
		interrupts = <GIC_SPI 581 IRQ_TYPE_LEVEL_HIGH>;
		qcom,mport = <0>;
		qcom,hw-timer-hz = <19200000>;
		qcom,count-unit = <0x10000>;
		qcom,target-dev = <&qcom_llcc_dcvs_hw>;
		qcom,second-vote = <&qcom_llcc_l3_vote>;
	};

	bwmon_ddr: qcom,bwmon-ddr@24091000 {
		compatible = "qcom,bwmon5";
		reg = <0x24091000 0x1000>;
		reg-names = "base";
		interrupts = <GIC_SPI 81 IRQ_TYPE_LEVEL_HIGH>;
		qcom,hw-timer-hz = <19200000>;
		qcom,count-unit = <0x10000>;
		qcom,target-dev = <&qcom_ddr_dcvs_hw>;
	};

	thermal_zones: thermal-zones {
	};

	google,debug-kinfo {
		compatible = "google,debug-kinfo";
		memory-region = <&kinfo_mem>;
	};

	spmi_bus: spmi0_bus: qcom,spmi@c42d000 {
		compatible = "qcom,spmi-pmic-arb";
		reg = <0xc42d000 0x4000>,
		      <0xc400000 0x3000>,
		      <0xc500000 0x400000>,
		      <0xc440000 0x80000>,
		      <0xc4c0000 0x10000>;
		reg-names = "cnfg", "core", "chnls", "obsrvr", "intr";
		interrupts-extended = <&pdc 1 IRQ_TYPE_LEVEL_HIGH>;
		interrupt-names = "periph_irq";
		interrupt-controller;
		#interrupt-cells = <4>;
		#address-cells = <2>;
		#size-cells = <0>;
		cell-index = <0>;
		qcom,channel = <0>;
		qcom,ee = <0>;
		qcom,bus-id = <0>;
	};

	spmi1_bus: qcom,spmi@c432000 {
		compatible = "qcom,spmi-pmic-arb";
		reg = <0xc432000 0x4000>,
		      <0xc400000 0x3000>,
		      <0xc500000 0x400000>,
		      <0xc440000 0x80000>,
		      <0xc4d0000 0x10000>;
		reg-names = "cnfg", "core", "chnls", "obsrvr", "intr";
		interrupts-extended = <&pdc 3 IRQ_TYPE_LEVEL_HIGH>;
		interrupt-names = "periph_irq";
		interrupt-controller;
		#interrupt-cells = <4>;
		#address-cells = <2>;
		#size-cells = <0>;
		cell-index = <0>;
		qcom,channel = <0>;
		qcom,ee = <0>;
		qcom,bus-id = <1>;
		depends-on-supply = <&spmi0_bus>;
	};

	spmi0_debug_bus: qcom,spmi-debug@10b14000 {
		compatible = "qcom,spmi-pmic-arb-debug";
		reg = <0x10b14000 0x60>, <0x221c8784 0x4>;
		reg-names = "core", "fuse";
		clocks = <&aoss_qmp>;
		clock-names = "core_clk";
		qcom,fuse-enable-bit = <18>;
		#address-cells = <2>;
		#size-cells = <0>;
		depends-on-supply = <&spmi1_bus>;
		depends-on2-supply = <&smb1394_glink_debug>;

		qcom,pmk8550-debug@0 {
			compatible = "qcom,spmi-pmic";
			reg = <0 SPMI_USID>;
			#address-cells = <2>;
			#size-cells = <0>;
			qcom,can-sleep;
		};

		qcom,pmxr2230-debug@1 {
			compatible = "qcom,spmi-pmic";
			reg = <1 SPMI_USID>;
			#address-cells = <2>;
			#size-cells = <0>;
			qcom,can-sleep;
		};

		qcom,pm8550vs-debug@2 {
			compatible = "qcom,spmi-pmic";
			reg = <2 SPMI_USID>;
			#address-cells = <2>;
			#size-cells = <0>;
			qcom,can-sleep;
		};

		qcom,pm8550vs-debug@3 {
			compatible = "qcom,spmi-pmic";
			reg = <3 SPMI_USID>;
			#address-cells = <2>;
			#size-cells = <0>;
			qcom,can-sleep;
		};

		qcom,pmr735d-debug@4 {
			compatible = "qcom,spmi-pmic";
			reg = <4 SPMI_USID>;
			#address-cells = <2>;
			#size-cells = <0>;
			qcom,can-sleep;
		};

		qcom,pmr735a-debug@5 {
			compatible = "qcom,spmi-pmic";
			reg = <5 SPMI_USID>;
			#address-cells = <2>;
			#size-cells = <0>;
			qcom,can-sleep;
		};

		qcom,pm8010-debug@c {
			compatible = "qcom,spmi-pmic";
			reg = <12 SPMI_USID>;
			#address-cells = <2>;
			#size-cells = <0>;
			qcom,can-sleep;
		};

		qcom,pm8010-debug@d {
			compatible = "qcom,spmi-pmic";
			reg = <13 SPMI_USID>;
			#address-cells = <2>;
			#size-cells = <0>;
			qcom,can-sleep;
		};
	};

	qcom,pmic_glink {
		compatible = "qcom,pmic-glink";
		qcom,pmic-glink-channel = "PMIC_RTR_ADSP_APPS";
		qcom,subsys-name = "lpass";
		qcom,protection-domain = "tms/servreg", "msm/adsp/charger_pd";
		depends-on-supply = <&ipcc_mproc>;

		battery_charger: qcom,battery_charger {
			compatible = "qcom,battery-charger";
		};

		ucsi: qcom,ucsi {
			compatible = "qcom,ucsi-glink";
			connector {
				port {
					usb_port0_connector: endpoint {
						remote-endpoint = <&usb_port0>;
					};
				};
			};
		};

		altmode: qcom,altmode {
			compatible = "qcom,altmode-glink";
			#altmode-cells = <1>;
		};
	};

	qcom,pmic_glink_log {
		compatible = "qcom,pmic-glink";
		qcom,pmic-glink-channel = "PMIC_LOGS_ADSP_APPS";

		qcom,battery_debug {
			compatible = "qcom,battery-debug";
		};

		qcom,charger_ulog_glink {
			compatible = "qcom,charger-ulog-glink";
		};

		pmic_glink_debug: qcom,pmic_glink_debug {
			compatible = "qcom,pmic-glink-debug";
			#address-cells = <1>;
			#size-cells = <0>;
			depends-on-supply = <&spmi1_bus>;

			/* Primary SPMI bus */
			glink_debug_spmi0:
			spmi@0 {
				reg = <0>;
				#address-cells = <2>;
				#size-cells = <0>;

				qcom,pm7550ba-debug@7 {
					compatible = "qcom,spmi-pmic";
					reg = <7 SPMI_USID>;
					qcom,can-sleep;
				};
			};

			/* Secondary SPMI bus */
			spmi@1 {
				reg = <1>;
				#address-cells = <2>;
				#size-cells = <0>;

				smb1394_glink_debug: qcom,smb1394-debug@9 {
					compatible = "qcom,spmi-pmic";
					reg = <9 SPMI_USID>;
					qcom,can-sleep;
				};

				qcom,smb1394-debug@b {
					compatible = "qcom,spmi-pmic";
					reg = <11 SPMI_USID>;
					qcom,can-sleep;
				};

				qcom,smb1398-debug@d {
					compatible = "qcom,spmi-pmic";
					reg = <13 SPMI_USID>;
					qcom,can-sleep;
				};
			};
		};

		pmic_glink_adc: qcom,glink-adc {
			compatible = "qcom,glink-adc";
			#address-cells = <1>;
			#size-cells = <0>;
			#io-channel-cells = <1>;
			status = "disabled";
		};
	};
};

&firmware {
	qcom_scm {
		compatible = "qcom,scm";
		qcom,dload-mode = <&tcsr 0x19000>;
	};

	android {
		compatible = "android,firmware";
		vbmeta {
			compatible = "android,vbmeta";
			parts = "vbmeta,boot,system,vendor,dtbo,recovery";
		};
	};

	qcom_smcinvoke {
		compatible = "qcom,smcinvoke";
	};

	qtee_shmbridge {
		compatible = "qcom,tee-shared-memory-bridge";
	};
};

#include "crow-pinctrl.dtsi"
#include "crow-usb.dtsi"
#include "crow-regulators.dtsi"
#include "kalama-gdsc.dtsi"
#include "crow-qupv3.dtsi"
#include "msm-rdbg.dtsi"
#include "ipcc-test-crow.dtsi"

&qupv3_se5_2uart {
	status = "ok";
};

&cam_cc_camss_top_gdsc {
	parent-supply = <&VDD_MXC_LEVEL>;
	clocks = <&gcc GCC_CAMERA_AHB_CLK>;
	clock-names = "ahb_clk";
	interconnects = <&mmss_noc MASTER_CAMNOC_HF &mmss_noc SLAVE_MNOC_HF_MEM_NOC>;
	interconnect-names = "mmnoc";
	status = "ok";
};

&disp_cc_mdss_core_gdsc {
	clocks = <&gcc GCC_DISP_AHB_CLK>;
	clock-names = "ahb_clk";
	parent-supply = <&VDD_CX_LEVEL>;
	status = "ok";
};

&disp_cc_mdss_core_int2_gdsc {
	clocks = <&gcc GCC_DISP_AHB_CLK>;
	clock-names = "ahb_clk";
	parent-supply = <&VDD_CX_LEVEL>;
	status = "ok";
};

&gcc_pcie_0_gdsc {
	parent-supply = <&VDD_CX_LEVEL>;
	qcom,collapse-vote = <&gcc_apcs_gdsc_vote_ctrl &gcc_apcs_gdsc_sleep_ctrl 0>;
	status = "ok";
};

&gcc_pcie_0_phy_gdsc {
	parent-supply = <&VDD_MXA_LEVEL>;
	qcom,collapse-vote = <&gcc_apcs_gdsc_vote_ctrl &gcc_apcs_gdsc_sleep_ctrl 2>;
	status = "ok";
};

&gcc_pcie_1_gdsc {
	parent-supply = <&VDD_CX_LEVEL>;
	qcom,collapse-vote = <&gcc_apcs_gdsc_vote_ctrl &gcc_apcs_gdsc_sleep_ctrl 3>;
	status = "ok";
};

&gcc_pcie_1_phy_gdsc {
	parent-supply = <&VDD_MXA_LEVEL>;
	qcom,collapse-vote = <&gcc_apcs_gdsc_vote_ctrl &gcc_apcs_gdsc_sleep_ctrl 4>;
	status = "ok";
};

&gcc_ufs_mem_phy_gdsc {
	parent-supply = <&VDD_MXA_LEVEL>;
	status = "ok";
};

&gcc_ufs_phy_gdsc {
	parent-supply = <&VDD_CX_LEVEL>;
	status = "ok";
};

&gcc_usb30_prim_gdsc {
	parent-supply = <&VDD_CX_LEVEL>;
	status = "ok";
};

&gcc_usb3_phy_gdsc {
	parent-supply = <&VDD_MXA_LEVEL>;
	status = "ok";
};

&gpu_cc_cx_gdsc {
	parent-supply = <&VDD_CX_LEVEL>;
	clocks = <&gcc GCC_GPU_CFG_AHB_CLK>;
	clock-names = "ahb_clk";
	status = "ok";
};

&gpu_cc_gx_gdsc {
	parent-supply = <&VDD_GFX_MXC_VOTER_LEVEL>;
	clocks = <&gcc GCC_GPU_CFG_AHB_CLK>;
	clock-names = "ahb_clk";
	status = "ok";
};

&video_cc_mvs0_gdsc {
	reg = <0xaaf805c 0x4>;
	clocks = <&gcc GCC_VIDEO_AHB_CLK>;
	clock-names = "ahb_clk";
	parent-supply = <&VDD_MXC_LEVEL>;
	interconnects = <&mmss_noc MASTER_CAMNOC_HF &mmss_noc SLAVE_MNOC_HF_MEM_NOC>;
	interconnect-names = "mmnoc";
	status = "ok";
};

&video_cc_mvs0c_gdsc {
	reg = <0xaaf8034 0x4>;
	clocks = <&gcc GCC_VIDEO_AHB_CLK>;
	clock-names = "ahb_clk";
	parent-supply = <&VDD_MXC_LEVEL>;
	interconnects = <&mmss_noc MASTER_CAMNOC_HF &mmss_noc SLAVE_MNOC_HF_MEM_NOC>;
	interconnect-names = "mmnoc";
	status = "ok";
};

#include "crow-thermal.dtsi"
